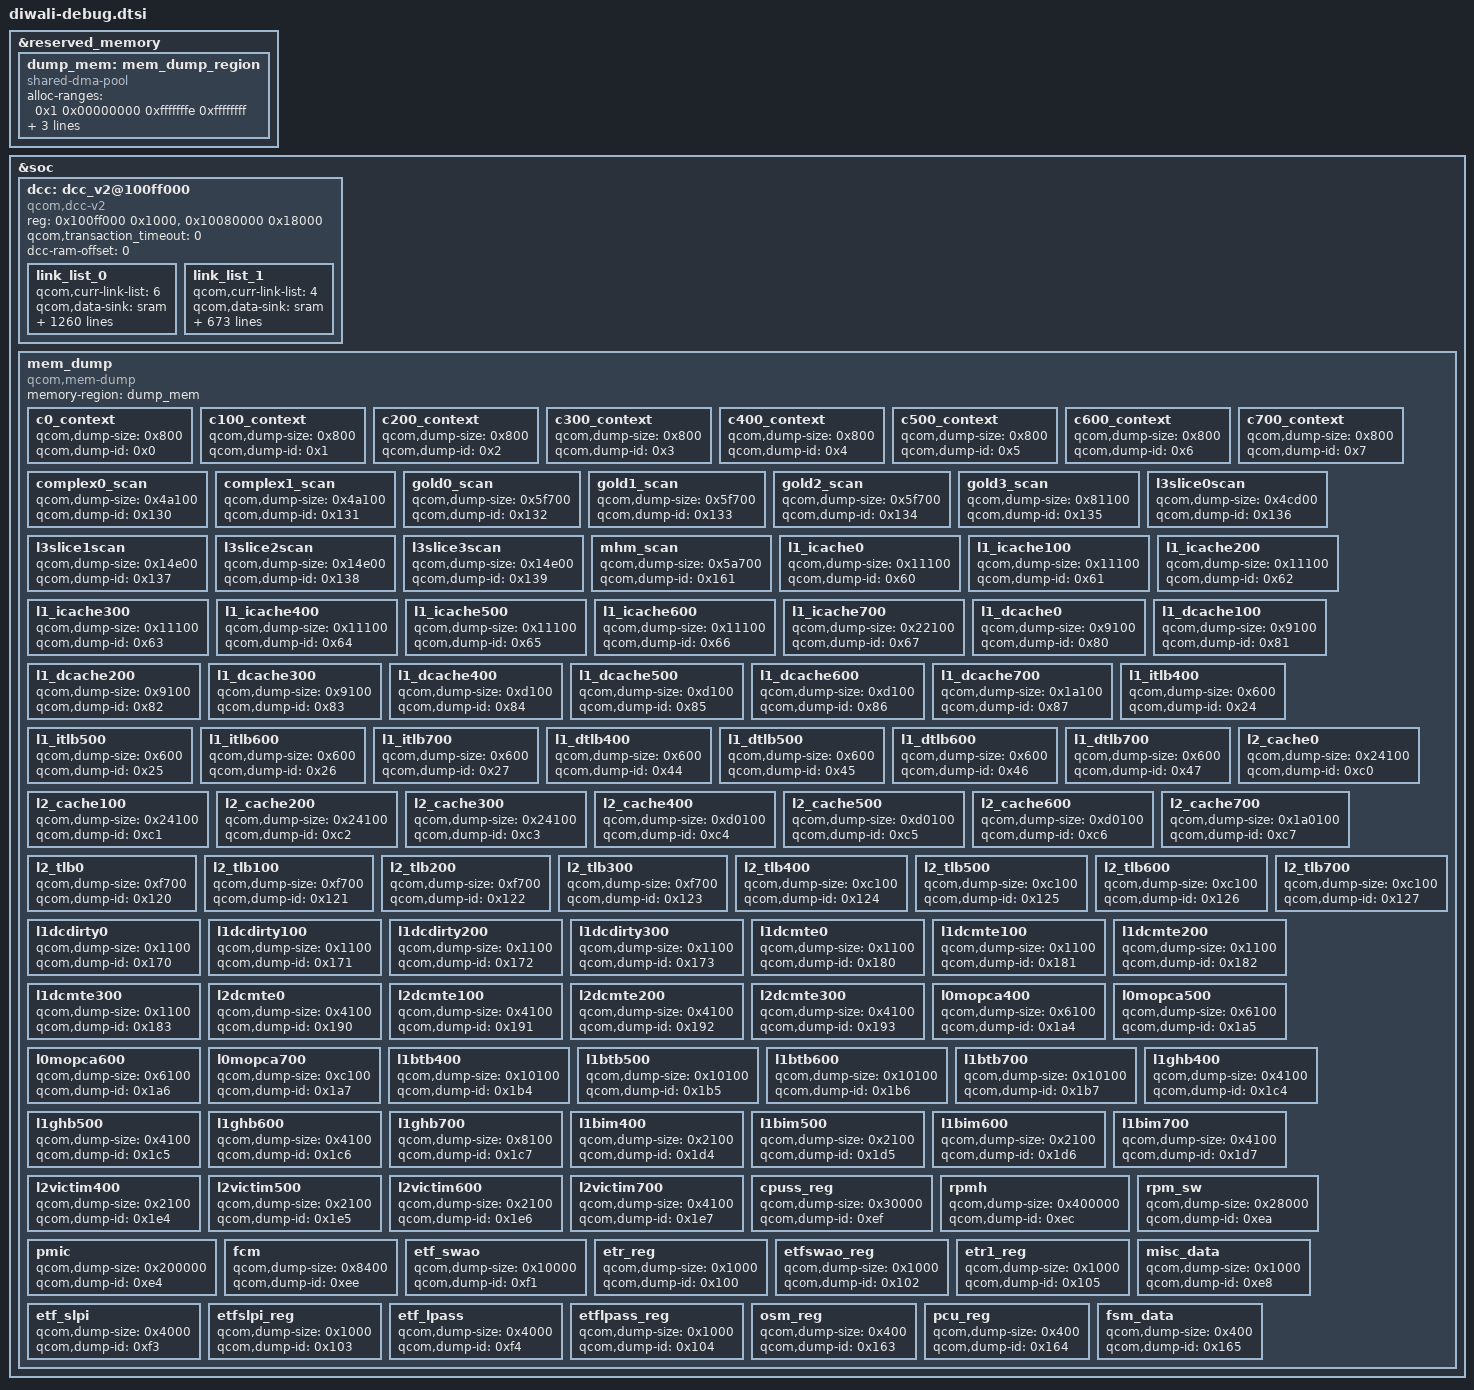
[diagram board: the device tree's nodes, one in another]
#include <dt-bindings/soc/qcom,dcc_v2.h>

&reserved_memory {
	#address-cells = <2>;
	#size-cells = <2>;
	ranges;

	dump_mem: mem_dump_region {
		compatible = "shared-dma-pool";
		alloc-ranges = <0x1 0x00000000 0xfffffffe 0xffffffff>;
		reusable;
		alignment = <0x0 0x400000>;
		size = <0 0x1400000>;
	};
};

&soc {
	dcc: dcc_v2@100ff000 {
		compatible = "qcom,dcc-v2";
		reg = <0x100ff000 0x1000>,
			<0x10080000 0x18000>;

		qcom,transaction_timeout = <0>;

		reg-names = "dcc-base", "dcc-ram-base";
		dcc-ram-offset = <0>;

		link_list_0 {
			qcom,curr-link-list = <6>;
			qcom,data-sink = "sram";
			qcom,link-list = <DCC_READ 0xc222004 1 0>,
			<DCC_READ 0xc263014 1 0>,
			<DCC_READ 0xc2630e0 1 0>,
			<DCC_READ 0xc2630ec 1 0>,
			<DCC_READ 0xc2630a0 16 0>,
			<DCC_READ 0xc2630e8 1 0>,
			<DCC_READ 0xc26313c 1 0>,
			<DCC_READ 0xc223004 1 0>,
			<DCC_READ 0xc265014 1 0>,
			<DCC_READ 0xc2650e0 1 0>,
			<DCC_READ 0xc2650ec 1 0>,
			<DCC_READ 0xc2650a0 16 0>,
			<DCC_READ 0xc2650e8 1 0>,
			<DCC_READ 0xc26513c 1 0>,
			<DCC_READ 0x1780005c 1 0>,
			<DCC_READ 0x1781005c 1 0>,
			<DCC_READ 0x1782005c 1 0>,
			<DCC_READ 0x1783005c 1 0>,
			<DCC_READ 0x1784005c 1 0>,
			<DCC_READ 0x1785005c 1 0>,
			<DCC_READ 0x1786005c 1 0>,
			<DCC_READ 0x1787005c 1 0>,
			<DCC_READ 0x1740003c 1 0>,
			<DCC_READ 0x17600238 1 0>,
			<DCC_READ 0x17600240 11 0>,
			<DCC_READ 0x17600530 1 0>,
			<DCC_READ 0x1760051c 1 0>,
			<DCC_READ 0x17600524 1 0>,
			<DCC_READ 0x1760052c 1 0>,
			<DCC_READ 0x17600518 1 0>,
			<DCC_READ 0x17600520 1 0>,
			<DCC_READ 0x17600528 1 0>,
			<DCC_READ 0x17600404 3 0>,
			<DCC_READ 0x1760041c 3 0>,
			<DCC_READ 0x17600434 1 0>,
			<DCC_READ 0x1760043c 2 0>,
			<DCC_READ 0x17400438 1 0>,
			<DCC_READ 0x17600044 1 0>,
			<DCC_READ 0x17600500 1 0>,
			<DCC_READ 0x17600504 5 0>,
			<DCC_READ 0x17900908 1 0>,
			<DCC_READ 0x17900c18 1 0>,
			<DCC_READ 0x17901908 1 0>,
			<DCC_READ 0x17901c18 1 0>,
			<DCC_READ 0x17b90810 1 0>,
			<DCC_READ 0x17b90c50 1 0>,
			<DCC_READ 0x17b90814 1 0>,
			<DCC_READ 0x17b90c54 1 0>,
			<DCC_READ 0x17b90818 1 0>,
			<DCC_READ 0x17b90c58 1 0>,
			<DCC_READ 0x17b93a84 2 0>,
			<DCC_READ 0x17ba0810 1 0>,
			<DCC_READ 0x17ba0c50 1 0>,
			<DCC_READ 0x17ba0814 1 0>,
			<DCC_READ 0x17ba0c54 1 0>,
			<DCC_READ 0x17ba0818 1 0>,
			<DCC_READ 0x17ba0c58 1 0>,
			<DCC_READ 0x17ba3a84 2 0>,
			<DCC_READ 0x17b93500 80 0>,
			<DCC_READ 0x17ba3500 80 0>,
			<DCC_READ 0x17a80000 16 0>,
			<DCC_READ 0x17a82000 16 0>,
			<DCC_READ 0x17a84000 16 0>,
			<DCC_READ 0x17a86000 16 0>,
			<DCC_READ 0x17aa0000 44 0>,
			<DCC_READ 0x17aa00fc 16 0>,
			<DCC_READ 0x17aa0200 2 0>,
			<DCC_READ 0x17aa0300 1 0>,
			<DCC_READ 0x17aa0400 1 0>,
			<DCC_READ 0x17aa0500 1 0>,
			<DCC_READ 0x17aa0600 1 0>,
			<DCC_READ 0x17aa0700 5 0>,
			<DCC_WRITE 0x17a80000 0x8007 0>,
			<DCC_READ 0x17a80000 1 0>,
			<DCC_WRITE 0x17a80024 0x0 0>,
			<DCC_READ 0x17a80024 1 0>,
			<DCC_WRITE 0x17a80020 0x0 0>,
			<DCC_READ 0x17a80020 1 0>,
			<DCC_READ 0x17a80038 1 0>,
			<DCC_WRITE 0x17a80020 0x40 0>,
			<DCC_READ 0x17a80020 1 0>,
			<DCC_READ 0x17a80038 1 0>,
			<DCC_WRITE 0x17a80020 0x80 0>,
			<DCC_READ 0x17a80020 1 0>,
			<DCC_READ 0x17a80038 1 0>,
			<DCC_WRITE 0x17a80020 0xc0 0>,
			<DCC_READ 0x17a80020 1 0>,
			<DCC_READ 0x17a80038 1 0>,
			<DCC_WRITE 0x17a80020 0x100 0>,
			<DCC_READ 0x17a80020 1 0>,
			<DCC_READ 0x17a80038 1 0>,
			<DCC_WRITE 0x17a80020 0x140 0>,
			<DCC_READ 0x17a80020 1 0>,
			<DCC_READ 0x17a80038 1 0>,
			<DCC_WRITE 0x17a80020 0x180 0>,
			<DCC_READ 0x17a80020 1 0>,
			<DCC_READ 0x17a80038 1 0>,
			<DCC_WRITE 0x17a80020 0x1c0 0>,
			<DCC_READ 0x17a80020 1 0>,
			<DCC_READ 0x17a80038 1 0>,
			<DCC_WRITE 0x17a80020 0x200 0>,
			<DCC_READ 0x17a80020 1 0>,
			<DCC_READ 0x17a80038 1 0>,
			<DCC_WRITE 0x17a80020 0x240 0>,
			<DCC_READ 0x17a80020 1 0>,
			<DCC_READ 0x17a80038 1 0>,
			<DCC_WRITE 0x17a80020 0x280 0>,
			<DCC_READ 0x17a80020 1 0>,
			<DCC_READ 0x17a80038 1 0>,
			<DCC_WRITE 0x17a80020 0x2c0 0>,
			<DCC_READ 0x17a80020 1 0>,
			<DCC_READ 0x17a80038 1 0>,
			<DCC_WRITE 0x17a80020 0x300 0>,
			<DCC_READ 0x17a80020 1 0>,
			<DCC_READ 0x17a80038 1 0>,
			<DCC_WRITE 0x17a80020 0x340 0>,
			<DCC_READ 0x17a80020 1 0>,
			<DCC_READ 0x17a80038 1 0>,
			<DCC_WRITE 0x17a80020 0x380 0>,
			<DCC_READ 0x17a80020 1 0>,
			<DCC_READ 0x17a80038 1 0>,
			<DCC_WRITE 0x17a80020 0x3c0 0>,
			<DCC_READ 0x17a80020 1 0>,
			<DCC_READ 0x17a80038 1 0>,
			<DCC_WRITE 0x17a80024 0x4000 0>,
			<DCC_READ 0x17a80024 1 0>,
			<DCC_WRITE 0x17a80020 0x0 0>,
			<DCC_READ 0x17a80020 1 0>,
			<DCC_WRITE 0x17a80020 0x0 0>,
			<DCC_READ 0x17a80020 1 0>,
			<DCC_WRITE 0x17a80020 0x0 0>,
			<DCC_READ 0x17a80020 1 0>,
			<DCC_READ 0x17a80038 1 0>,
			<DCC_WRITE 0x17a80020 0x40 0>,
			<DCC_READ 0x17a80020 1 0>,
			<DCC_READ 0x17a80038 1 0>,
			<DCC_WRITE 0x17a82000 0x8007 0>,
			<DCC_READ 0x17a82000 1 0>,
			<DCC_WRITE 0x17a82024 0x0 0>,
			<DCC_READ 0x17a82024 1 0>,
			<DCC_WRITE 0x17a82020 0x0 0>,
			<DCC_READ 0x17a82020 1 0>,
			<DCC_READ 0x17a82038 1 0>,
			<DCC_WRITE 0x17a82020 0x40 0>,
			<DCC_READ 0x17a82020 1 0>,
			<DCC_READ 0x17a82038 1 0>,
			<DCC_WRITE 0x17a82020 0x80 0>,
			<DCC_READ 0x17a82020 1 0>,
			<DCC_READ 0x17a82038 1 0>,
			<DCC_WRITE 0x17a82020 0xc0 0>,
			<DCC_READ 0x17a82020 1 0>,
			<DCC_READ 0x17a82038 1 0>,
			<DCC_WRITE 0x17a82020 0x100 0>,
			<DCC_READ 0x17a82020 1 0>,
			<DCC_READ 0x17a82038 1 0>,
			<DCC_WRITE 0x17a82020 0x140 0>,
			<DCC_READ 0x17a82020 1 0>,
			<DCC_READ 0x17a82038 1 0>,
			<DCC_WRITE 0x17a82020 0x180 0>,
			<DCC_READ 0x17a82020 1 0>,
			<DCC_READ 0x17a82038 1 0>,
			<DCC_WRITE 0x17a82020 0x1c0 0>,
			<DCC_READ 0x17a82020 1 0>,
			<DCC_READ 0x17a82038 1 0>,
			<DCC_WRITE 0x17a82020 0x200 0>,
			<DCC_READ 0x17a82020 1 0>,
			<DCC_READ 0x17a82038 1 0>,
			<DCC_WRITE 0x17a82020 0x240 0>,
			<DCC_READ 0x17a82020 1 0>,
			<DCC_READ 0x17a82038 1 0>,
			<DCC_WRITE 0x17a82020 0x280 0>,
			<DCC_READ 0x17a82020 1 0>,
			<DCC_READ 0x17a82038 1 0>,
			<DCC_WRITE 0x17a82020 0x2c0 0>,
			<DCC_READ 0x17a82020 1 0>,
			<DCC_READ 0x17a82038 1 0>,
			<DCC_WRITE 0x17a82020 0x300 0>,
			<DCC_READ 0x17a82020 1 0>,
			<DCC_READ 0x17a82038 1 0>,
			<DCC_WRITE 0x17a82020 0x340 0>,
			<DCC_READ 0x17a82020 1 0>,
			<DCC_READ 0x17a82038 1 0>,
			<DCC_WRITE 0x17a82020 0x380 0>,
			<DCC_READ 0x17a82020 1 0>,
			<DCC_READ 0x17a82038 1 0>,
			<DCC_WRITE 0x17a82020 0x3c0 0>,
			<DCC_READ 0x17a82020 1 0>,
			<DCC_READ 0x17a82038 1 0>,
			<DCC_WRITE 0x17a82024 0x4000 0>,
			<DCC_READ 0x17a82024 1 0>,
			<DCC_WRITE 0x17a82020 0x0 0>,
			<DCC_READ 0x17a82020 1 0>,
			<DCC_WRITE 0x17a82020 0x0 0>,
			<DCC_READ 0x17a82020 1 0>,
			<DCC_WRITE 0x17a82020 0x0 0>,
			<DCC_READ 0x17a82020 1 0>,
			<DCC_READ 0x17a82038 1 0>,
			<DCC_WRITE 0x17a82020 0x40 0>,
			<DCC_READ 0x17a82020 1 0>,
			<DCC_READ 0x17a82038 1 0>,
			<DCC_WRITE 0x17a84000 0x8007 0>,
			<DCC_READ 0x17a84000 1 0>,
			<DCC_WRITE 0x17a84024 0x0 0>,
			<DCC_READ 0x17a84024 1 0>,
			<DCC_WRITE 0x17a84020 0x0 0>,
			<DCC_READ 0x17a84020 1 0>,
			<DCC_READ 0x17a84038 1 0>,
			<DCC_WRITE 0x17a84020 0x40 0>,
			<DCC_READ 0x17a84020 1 0>,
			<DCC_READ 0x17a84038 1 0>,
			<DCC_WRITE 0x17a84020 0x80 0>,
			<DCC_READ 0x17a84020 1 0>,
			<DCC_READ 0x17a84038 1 0>,
			<DCC_WRITE 0x17a84020 0xc0 0>,
			<DCC_READ 0x17a84020 1 0>,
			<DCC_READ 0x17a84038 1 0>,
			<DCC_WRITE 0x17a84020 0x100 0>,
			<DCC_READ 0x17a84020 1 0>,
			<DCC_READ 0x17a84038 1 0>,
			<DCC_WRITE 0x17a84020 0x140 0>,
			<DCC_READ 0x17a84020 1 0>,
			<DCC_READ 0x17a84038 1 0>,
			<DCC_WRITE 0x17a84020 0x180 0>,
			<DCC_READ 0x17a84020 1 0>,
			<DCC_READ 0x17a84038 1 0>,
			<DCC_WRITE 0x17a84020 0x1c0 0>,
			<DCC_READ 0x17a84020 1 0>,
			<DCC_READ 0x17a84038 1 0>,
			<DCC_WRITE 0x17a84020 0x200 0>,
			<DCC_READ 0x17a84020 1 0>,
			<DCC_READ 0x17a84038 1 0>,
			<DCC_WRITE 0x17a84020 0x240 0>,
			<DCC_READ 0x17a84020 1 0>,
			<DCC_READ 0x17a84038 1 0>,
			<DCC_WRITE 0x17a84020 0x280 0>,
			<DCC_READ 0x17a84020 1 0>,
			<DCC_READ 0x17a84038 1 0>,
			<DCC_WRITE 0x17a84020 0x2c0 0>,
			<DCC_READ 0x17a84020 1 0>,
			<DCC_READ 0x17a84038 1 0>,
			<DCC_WRITE 0x17a84020 0x300 0>,
			<DCC_READ 0x17a84020 1 0>,
			<DCC_READ 0x17a84038 1 0>,
			<DCC_WRITE 0x17a84020 0x340 0>,
			<DCC_READ 0x17a84020 1 0>,
			<DCC_READ 0x17a84038 1 0>,
			<DCC_WRITE 0x17a84020 0x380 0>,
			<DCC_READ 0x17a84020 1 0>,
			<DCC_READ 0x17a84038 1 0>,
			<DCC_WRITE 0x17a84020 0x3c0 0>,
			<DCC_READ 0x17a84020 1 0>,
			<DCC_READ 0x17a84038 1 0>,
			<DCC_WRITE 0x17a84024 0x4000 0>,
			<DCC_READ 0x17a84024 1 0>,
			<DCC_WRITE 0x17a84020 0x0 0>,
			<DCC_READ 0x17a84020 1 0>,
			<DCC_WRITE 0x17a84020 0x0 0>,
			<DCC_READ 0x17a84020 1 0>,
			<DCC_WRITE 0x17a84020 0x0 0>,
			<DCC_READ 0x17a84020 1 0>,
			<DCC_READ 0x17a84038 1 0>,
			<DCC_WRITE 0x17a84020 0x40 0>,
			<DCC_READ 0x17a84020 1 0>,
			<DCC_READ 0x17a84038 1 0>,
			<DCC_WRITE 0x17a86000 0x8007 0>,
			<DCC_READ 0x17a86000 1 0>,
			<DCC_WRITE 0x17a86024 0x0 0>,
			<DCC_READ 0x17a86024 1 0>,
			<DCC_WRITE 0x17a86020 0x0 0>,
			<DCC_READ 0x17a86020 1 0>,
			<DCC_READ 0x17a86038 1 0>,
			<DCC_WRITE 0x17a86020 0x40 0>,
			<DCC_READ 0x17a86020 1 0>,
			<DCC_READ 0x17a86038 1 0>,
			<DCC_WRITE 0x17a86020 0x80 0>,
			<DCC_READ 0x17a86020 1 0>,
			<DCC_READ 0x17a86038 1 0>,
			<DCC_WRITE 0x17a86020 0xc0 0>,
			<DCC_READ 0x17a86020 1 0>,
			<DCC_READ 0x17a86038 1 0>,
			<DCC_WRITE 0x17a86020 0x100 0>,
			<DCC_READ 0x17a86020 1 0>,
			<DCC_READ 0x17a86038 1 0>,
			<DCC_WRITE 0x17a86020 0x140 0>,
			<DCC_READ 0x17a86020 1 0>,
			<DCC_READ 0x17a86038 1 0>,
			<DCC_WRITE 0x17a86020 0x180 0>,
			<DCC_READ 0x17a86020 1 0>,
			<DCC_READ 0x17a86038 1 0>,
			<DCC_WRITE 0x17a86020 0x1c0 0>,
			<DCC_READ 0x17a86020 1 0>,
			<DCC_READ 0x17a86038 1 0>,
			<DCC_WRITE 0x17a86020 0x200 0>,
			<DCC_READ 0x17a86020 1 0>,
			<DCC_READ 0x17a86038 1 0>,
			<DCC_WRITE 0x17a86020 0x240 0>,
			<DCC_READ 0x17a86020 1 0>,
			<DCC_READ 0x17a86038 1 0>,
			<DCC_WRITE 0x17a86020 0x280 0>,
			<DCC_READ 0x17a86020 1 0>,
			<DCC_READ 0x17a86038 1 0>,
			<DCC_WRITE 0x17a86020 0x2c0 0>,
			<DCC_READ 0x17a86020 1 0>,
			<DCC_READ 0x17a86038 1 0>,
			<DCC_WRITE 0x17a86020 0x300 0>,
			<DCC_READ 0x17a86020 1 0>,
			<DCC_READ 0x17a86038 1 0>,
			<DCC_WRITE 0x17a86020 0x340 0>,
			<DCC_READ 0x17a86020 1 0>,
			<DCC_READ 0x17a86038 1 0>,
			<DCC_WRITE 0x17a86020 0x380 0>,
			<DCC_READ 0x17a86020 1 0>,
			<DCC_READ 0x17a86038 1 0>,
			<DCC_WRITE 0x17a86020 0x3c0 0>,
			<DCC_READ 0x17a86020 1 0>,
			<DCC_READ 0x17a86038 1 0>,
			<DCC_WRITE 0x17a86024 0x4000 0>,
			<DCC_READ 0x17a86024 1 0>,
			<DCC_WRITE 0x17a86020 0x0 0>,
			<DCC_READ 0x17a86020 1 0>,
			<DCC_WRITE 0x17a86020 0x0 0>,
			<DCC_READ 0x17a86020 1 0>,
			<DCC_WRITE 0x17a86020 0x0 0>,
			<DCC_READ 0x17a86020 1 0>,
			<DCC_READ 0x17a86038 1 0>,
			<DCC_WRITE 0x17a86020 0x40 0>,
			<DCC_READ 0x17a86020 1 0>,
			<DCC_READ 0x17a86038 1 0>,
			<DCC_READ 0xc201244 1 0>,
			<DCC_READ 0xc202244 1 0>,
			<DCC_READ 0x17b00000 1 0>,
			<DCC_READ 0x17a94030 1 0>,
			<DCC_READ 0x17a9408c 1 0>,
			<DCC_WRITE 0x17a9409c 0x78 0>,
			<DCC_WRITE 0x17a9409c 0x0  0>,
			<DCC_WRITE 0x17a94048 0x1  0>,
			<DCC_WRITE 0x17a94090 0x0  0>,
			<DCC_WRITE 0x17a94090 0x25 0>,
			<DCC_READ 0x17a94098 1 0>,
			<DCC_WRITE 0x17a94048 0x1d 0>,
			<DCC_WRITE 0x17a94090 0x0  0>,
			<DCC_WRITE 0x17a94090 0x25 0>,
			<DCC_READ 0x17a94098 1 0>,
			<DCC_READ 0x17a90030 1 0>,
			<DCC_READ 0x17a9008c 1 0>,
			<DCC_WRITE 0x17a9009c 0x78 0>,
			<DCC_WRITE 0x17a9009c 0x0  0>,
			<DCC_WRITE 0x17a90048 0x1  0>,
			<DCC_WRITE 0x17a90090 0x0  0>,
			<DCC_WRITE 0x17a90090 0x25 0>,
			<DCC_READ 0x17a90098 1 0>,
			<DCC_WRITE 0x17a90048 0x1d 0>,
			<DCC_WRITE 0x17a90090 0x0  0>,
			<DCC_WRITE 0x17a90090 0x25 0>,
			<DCC_READ 0x17a90098 1 0>,
			<DCC_READ 0x17a92030 1 0>,
			<DCC_READ 0x17a9208c 1 0>,
			<DCC_WRITE 0x17a9209c 0x78 0>,
			<DCC_WRITE 0x17a9209c 0x0  0>,
			<DCC_WRITE 0x17a92048 0x1  0>,
			<DCC_WRITE 0x17a92090 0x0  0>,
			<DCC_WRITE 0x17a92090 0x25 0>,
			<DCC_READ 0x17a92098 1 0>,
			<DCC_WRITE 0x17a92048 0x1d 0>,
			<DCC_WRITE 0x17a92090 0x0  0>,
			<DCC_WRITE 0x17a92090 0x25 0>,
			<DCC_READ 0x17a92098 1 0>,
			<DCC_READ 0x17a96030 1 0>,
			<DCC_READ 0x17a9608c 1 0>,
			<DCC_WRITE 0x17a9609c 0x78 0>,
			<DCC_WRITE 0x17a9609c 0x0  0>,
			<DCC_WRITE 0x17a96048 0x1  0>,
			<DCC_WRITE 0x17a96090 0x0  0>,
			<DCC_WRITE 0x17a96090 0x25 0>,
			<DCC_READ 0x17a96098 1 0>,
			<DCC_WRITE 0x17a96048 0x1d 0>,
			<DCC_WRITE 0x17a96090 0x0  0>,
			<DCC_WRITE 0x17a96090 0x25 0>,
			<DCC_READ 0x17a96098 1 0>,
			<DCC_READ 0x17d98020 1 0>,
			<DCC_READ 0x13822000 1 0>,
			<DCC_READ 0x221c21c4 1 0>,
			<DCC_READ 0x1fc8000 1 0>,
			<DCC_READ 0x17400038 1 0>,
			<DCC_READ 0x17d91020 1 0>,
			<DCC_READ 0x17d92020 1 0>,
			<DCC_READ 0x17d93020 1 0>,
			<DCC_READ 0x17d90020 1 0>,
			<DCC_READ 0x17d9134c 1 0>,
			<DCC_READ 0x17d9234c 1 0>,
			<DCC_READ 0x17d9334c 1 0>,
			<DCC_READ 0x17d9034c 1 0>,
			<DCC_READ 0x17d91300 1 0>,
			<DCC_READ 0x17d92300 1 0>,
			<DCC_READ 0x17d93300 1 0>,
			<DCC_READ 0x17d90300 1 0>,
			<DCC_READ 0x191b0040 1 0>,
			<DCC_READ 0x191b0048 1 0>,
			<DCC_READ 0x19180010 1 0>,
			<DCC_READ 0x19180020 6 0>,
			<DCC_READ 0x19181010 1 0>,
			<DCC_READ 0x19181020 6 0>,
			<DCC_READ 0x19100010 1 0>,
			<DCC_READ 0x19100020 6 0>,
			<DCC_READ 0x19140010 1 0>,
			<DCC_READ 0x19140020 6 0>,
			<DCC_READ 0x19180410 1 0>,
			<DCC_LOOP 0x10  0 0>,
			<DCC_READ 0x19180438 1 0>,
			<DCC_READ 0x19180430 2 0>,
			<DCC_READ 0x19180430 2 0>,
			<DCC_READ 0x19180430 2 0>,
			<DCC_READ 0x19180430 2 0>,
			<DCC_LOOP 0x1  0 0>,
			<DCC_READ 0x19180408 2 0>,
			<DCC_READ 0x19181410 1 0>,
			<DCC_LOOP 0x10  0 0>,
			<DCC_READ 0x19181438 1 0>,
			<DCC_READ 0x19181430 2 0>,
			<DCC_READ 0x19181430 2 0>,
			<DCC_READ 0x19181430 2 0>,
			<DCC_READ 0x19181430 2 0>,
			<DCC_LOOP 0x1  0 0>,
			<DCC_READ 0x19181408 2 0>,
			<DCC_READ 0x19100410 1 0>,
			<DCC_LOOP 0x40  0 0>,
			<DCC_READ 0x19100438 1 0>,
			<DCC_READ 0x19100430 2 0>,
			<DCC_READ 0x19100430 2 0>,
			<DCC_READ 0x19100430 2 0>,
			<DCC_READ 0x19100430 2 0>,
			<DCC_LOOP 0x1  0 0>,
			<DCC_READ 0x19100408 2 0>,
			<DCC_READ 0x19140410 1 0>,
			<DCC_LOOP 0x40  0 0>,
			<DCC_READ 0x19140438 1 0>,
			<DCC_READ 0x19140430 2 0>,
			<DCC_READ 0x19140430 2 0>,
			<DCC_READ 0x19140430 2 0>,
			<DCC_READ 0x19140430 2 0>,
			<DCC_LOOP 0x1  0 0>,
			<DCC_READ 0x19140408 2 0>,
			<DCC_READ 0x19191018 1 0>,
			<DCC_READ 0x19191008 1 0>,
			<DCC_READ 0x19191010 2 0>,
			<DCC_READ 0x19191010 2 0>,
			<DCC_READ 0x19191010 2 0>,
			<DCC_READ 0x19191010 2 0>,
			<DCC_READ 0x19191010 2 0>,
			<DCC_READ 0x19191010 2 0>,
			<DCC_READ 0x19191010 2 0>,
			<DCC_READ 0x19191010 2 0>,
			<DCC_READ 0x19191010 2 0>,
			<DCC_READ 0x1914d018 1 0>,
			<DCC_READ 0x1914d008 1 0>,
			<DCC_READ 0x1914d010 2 0>,
			<DCC_READ 0x1914d010 2 0>,
			<DCC_READ 0x1914d010 2 0>,
			<DCC_READ 0x1914d010 2 0>,
			<DCC_READ 0x1914d010 2 0>,
			<DCC_READ 0x1910d018 1 0>,
			<DCC_READ 0x1910d008 1 0>,
			<DCC_READ 0x1910d010 2 0>,
			<DCC_READ 0x1910d010 2 0>,
			<DCC_READ 0x1910d010 2 0>,
			<DCC_READ 0x1910d010 2 0>,
			<DCC_READ 0x1910d010 2 0>,
			<DCC_READ 0x19190018 1 0>,
			<DCC_READ 0x19190008 1 0>,
			<DCC_READ 0x19190010 2 0>,
			<DCC_READ 0x19190010 2 0>,
			<DCC_READ 0x19190010 2 0>,
			<DCC_READ 0x1914c018 1 0>,
			<DCC_READ 0x1914c008 1 0>,
			<DCC_READ 0x1914c010 2 0>,
			<DCC_READ 0x1914c010 2 0>,
			<DCC_READ 0x1914c010 2 0>,
			<DCC_READ 0x1914c010 2 0>,
			<DCC_READ 0x1910c018 1 0>,
			<DCC_READ 0x1910c008 1 0>,
			<DCC_READ 0x1910c010 2 0>,
			<DCC_READ 0x1910c010 2 0>,
			<DCC_READ 0x1910c010 2 0>,
			<DCC_READ 0x1910c010 2 0>,
			<DCC_READ 0x19121010 1 0>,
			<DCC_READ 0x19123010 1 0>,
			<DCC_READ 0x191a1010 1 0>,
			<DCC_READ 0x191a4010 1 0>,
			<DCC_READ 0x191a5010 1 0>,
			<DCC_READ 0x191a0010 1 0>,
			<DCC_READ 0x19160010 1 0>,
			<DCC_READ 0x19120010 1 0>,
			<DCC_READ 0x191a6010 1 0>,
			<DCC_READ 0x19122010 1 0>,
			<DCC_READ 0x191a2010 1 0>,
			<DCC_READ 0x191a3010 1 0>,
			<DCC_READ 0x19161010 1 0>,
			<DCC_READ 0x19162010 1 0>,
			<DCC_READ 0x19163010 1 0>,
			<DCC_READ 0x3d0201c 1 0>,
			<DCC_READ 0x3d00000 1 0>,
			<DCC_READ 0x3d00008 1 0>,
			<DCC_READ 0x3d00044 1 0>,
			<DCC_READ 0x3d00058 6 0>,
			<DCC_READ 0x3d0007c 20 0>,
			<DCC_READ 0x3d000e0 5 0>,
			<DCC_READ 0x3d00108 1 0>,
			<DCC_READ 0x3d00110 1 0>,
			<DCC_READ 0x3d0011c 1 0>,
			<DCC_READ 0x3d00124 2 0>,
			<DCC_READ 0x3d00140 1 0>,
			<DCC_READ 0x3d00158 1 0>,
			<DCC_READ 0x3d002b4 2 0>,
			<DCC_READ 0x3d002c0 1 0>,
			<DCC_READ 0x3d002d0 1 0>,
			<DCC_READ 0x3d002e0 1 0>,
			<DCC_READ 0x3d002f0 1 0>,
			<DCC_READ 0x3d00300 1 0>,
			<DCC_READ 0x3d00310 1 0>,
			<DCC_READ 0x3d00320 1 0>,
			<DCC_READ 0x3d00330 1 0>,
			<DCC_READ 0x3d00340 1 0>,
			<DCC_READ 0x3d00350 1 0>,
			<DCC_READ 0x3d00360 1 0>,
			<DCC_READ 0x3d00370 1 0>,
			<DCC_READ 0x3d00380 1 0>,
			<DCC_READ 0x3d00390 1 0>,
			<DCC_READ 0x3d003a0 1 0>,
			<DCC_READ 0x3d003b0 1 0>,
			<DCC_READ 0x3d003c0 1 0>,
			<DCC_READ 0x3d003d0 1 0>,
			<DCC_READ 0x3d003e0 1 0>,
			<DCC_READ 0x3d00400 1 0>,
			<DCC_READ 0x3d00410 8 0>,
			<DCC_READ 0x3d0043c 15 0>,
			<DCC_READ 0x3d00800 14 0>,
			<DCC_READ 0x3d00840 4 0>,
			<DCC_READ 0x3d00854 41 0>,
			<DCC_READ 0x3d01444 1 0>,
			<DCC_READ 0x3d014d4 1 0>,
			<DCC_READ 0x3d017f0 4 0>,
			<DCC_READ 0x3d99800 8 0>,
			<DCC_READ 0x3d99828 1 0>,
			<DCC_READ 0x3d9983c 1 0>,
			<DCC_READ 0x3d998ac 1 0>,
			<DCC_READ 0x18101c 2 0>,
			<DCC_READ 0x3d94000 2 0>,
			<DCC_READ 0x3d95000 4 0>,
			<DCC_READ 0x3d96000 4 0>,
			<DCC_READ 0x3d97000 4 0>,
			<DCC_READ 0x3d98000 4 0>,
			<DCC_READ 0x3d99000 6 0>,
			<DCC_READ 0x3d99050 10 0>,
			<DCC_READ 0x3d990a8 2 0>,
			<DCC_READ 0x3d990b8 3 0>,
			<DCC_READ 0x3d990c8 1 0>,
			<DCC_READ 0x3d99104 8 0>,
			<DCC_READ 0x3d99130 2 0>,
			<DCC_READ 0x3d9913c 7 0>,
			<DCC_READ 0x3d99198 3 0>,
			<DCC_READ 0x3d991e0 3 0>,
			<DCC_READ 0x3d99224 2 0>,
			<DCC_READ 0x3d99280 4 0>,
			<DCC_READ 0x3d992cc 3 0>,
			<DCC_READ 0x3d99314 3 0>,
			<DCC_READ 0x3d99358 3 0>,
			<DCC_READ 0x3d993a0 2 0>,
			<DCC_READ 0x3d993e4 4 0>,
			<DCC_READ 0x3d9942c 2 0>,
			<DCC_READ 0x3d99470 3 0>,
			<DCC_READ 0x3d99500 4 0>,
			<DCC_READ 0x3d99528 39 0>,
			<DCC_READ 0x3d90000 15 0>,
			<DCC_READ 0x3d91000 15 0>,
			<DCC_READ 0x3de0000 21 0>,
			<DCC_READ 0x3de00d0 1 0>,
			<DCC_READ 0x3de00d8 1 0>,
			<DCC_READ 0x3de0100 3 0>,
			<DCC_READ 0x3de0200 5 0>,
			<DCC_READ 0x3de0400 3 0>,
			<DCC_READ 0x3de0450 1 0>,
			<DCC_READ 0x3de0460 2 0>,
			<DCC_READ 0x3de0490 11 0>,
			<DCC_READ 0x3de0500 1 0>,
			<DCC_READ 0x3de0600 1 0>,
			<DCC_READ 0x3de0d00 2 0>,
			<DCC_READ 0x3de0d10 4 0>,
			<DCC_READ 0x3de0d30 5 0>,
			<DCC_READ 0x3de3d44 1 0>,
			<DCC_READ 0x3de3d4c 2 0>,
			<DCC_READ 0x3d8ec0c 1 0>,
			<DCC_READ 0x3d8ec14 2 0>,
			<DCC_READ 0x3d8ec30 3 0>,
			<DCC_READ 0x3d8ec40 4 0>,
			<DCC_READ 0x3d8ec54 1 0>,
			<DCC_READ 0x3d8eca0 1 0>,
			<DCC_READ 0x3d8ecc0 1 0>,
			<DCC_READ 0x3d7d018 3 0>,
			<DCC_READ 0x3d7e440 2 0>,
			<DCC_READ 0x3d7e480 2 0>,
			<DCC_READ 0x3d7e490 2 0>,
			<DCC_READ 0x3d7e4a0 2 0>,
			<DCC_READ 0x3d7e4b0 2 0>,
			<DCC_READ 0x3d7e5c0 10 0>,
			<DCC_READ 0x3d7e648 2 0>,
			<DCC_READ 0x3d7e658 9 0>,
			<DCC_READ 0x3d7e7c0 2 0>,
			<DCC_READ 0x17800010 1 0>,
			<DCC_READ 0x17800024 1 0>,
			<DCC_READ 0x17800038 6 0>,
			<DCC_READ 0x17800058 4 0>,
			<DCC_READ 0x1780006c 1 0>,
			<DCC_READ 0x178000f0 2 0>,
			<DCC_READ 0x17810010 1 0>,
			<DCC_READ 0x17810024 1 0>,
			<DCC_READ 0x17810038 6 0>,
			<DCC_READ 0x17810058 4 0>,
			<DCC_READ 0x1781006c 1 0>,
			<DCC_READ 0x178100f0 2 0>,
			<DCC_READ 0x17820010 1 0>,
			<DCC_READ 0x17820024 1 0>,
			<DCC_READ 0x17820038 6 0>,
			<DCC_READ 0x17820058 4 0>,
			<DCC_READ 0x178200f0 2 0>,
			<DCC_READ 0x17830010 1 0>,
			<DCC_READ 0x17830024 1 0>,
			<DCC_READ 0x17830038 6 0>,
			<DCC_READ 0x17830058 4 0>,
			<DCC_READ 0x178300f0 2 0>,
			<DCC_READ 0x17840010 1 0>,
			<DCC_READ 0x17840024 1 0>,
			<DCC_READ 0x17840038 6 0>,
			<DCC_READ 0x17840058 4 0>,
			<DCC_READ 0x178400f0 2 0>,
			<DCC_READ 0x17850010 1 0>,
			<DCC_READ 0x17850024 1 0>,
			<DCC_READ 0x17850038 6 0>,
			<DCC_READ 0x17850058 4 0>,
			<DCC_READ 0x178500f0 2 0>,
			<DCC_READ 0x17860010 1 0>,
			<DCC_READ 0x17860024 1 0>,
			<DCC_READ 0x17860038 6 0>,
			<DCC_READ 0x17860058 4 0>,
			<DCC_READ 0x178600f0 2 0>,
			<DCC_READ 0x17870010 1 0>,
			<DCC_READ 0x17870024 1 0>,
			<DCC_READ 0x17870038 6 0>,
			<DCC_READ 0x17870058 4 0>,
			<DCC_READ 0x178700f0 2 0>,
			<DCC_READ 0x178a0010 1 0>,
			<DCC_READ 0x178a0024 1 0>,
			<DCC_READ 0x178a0038 6 0>,
			<DCC_READ 0x178a006c 5 0>,
			<DCC_READ 0x178a0084 1 0>,
			<DCC_READ 0x178a00f4 5 0>,
			<DCC_READ 0x178a0118 9 0>,
			<DCC_READ 0x178a0158 5 0>,
			<DCC_READ 0x178a0170 2 0>,
			<DCC_READ 0x178a0188 5 0>,
			<DCC_READ 0x178a01ac 6 0>,
			<DCC_READ 0x178a01c8 1 0>,
			<DCC_READ 0x17880010 1 0>,
			<DCC_READ 0x17880024 1 0>,
			<DCC_READ 0x17880038 6 0>,
			<DCC_READ 0x17890010 1 0>,
			<DCC_READ 0x17890024 1 0>,
			<DCC_READ 0x17890038 6 0>,
			<DCC_READ 0x178a0204 1 0>,
			<DCC_READ 0x178a0244 1 0>,
			<DCC_READ 0x17e30000 1 0>,
			<DCC_READ 0x17e30008 1 0>,
			<DCC_READ 0x17e30010 1 0>,
			<DCC_READ 0x17e80000 1 0>,
			<DCC_READ 0x17e80008 1 0>,
			<DCC_READ 0x17e80010 1 0>,
			<DCC_READ 0x17f80000 1 0>,
			<DCC_READ 0x17f80008 1 0>,
			<DCC_READ 0x17f80010 1 0>,
			<DCC_READ 0x18080000 1 0>,
			<DCC_READ 0x18080008 1 0>,
			<DCC_READ 0x18080010 1 0>,
			<DCC_READ 0x18180000 1 0>,
			<DCC_READ 0x18180008 1 0>,
			<DCC_READ 0x18180010 1 0>,
			<DCC_READ 0x18280000 1 0>,
			<DCC_READ 0x18280008 1 0>,
			<DCC_READ 0x18280010 1 0>,
			<DCC_READ 0x18380000 1 0>,
			<DCC_READ 0x18380008 1 0>,
			<DCC_READ 0x18380010 1 0>,
			<DCC_READ 0x18480000 1 0>,
			<DCC_READ 0x18480008 1 0>,
			<DCC_READ 0x18480010 1 0>,
			<DCC_READ 0x18580000 1 0>,
			<DCC_READ 0x18580008 1 0>,
			<DCC_READ 0x18580010 1 0>,
			<DCC_READ 0x19080024 1 0>,
			<DCC_READ 0x1908002c 1 0>,
			<DCC_READ 0x19080034 1 0>,
			<DCC_READ 0x1908003c 1 0>,
			<DCC_READ 0x19080044 1 0>,
			<DCC_READ 0x1908004c 1 0>,
			<DCC_READ 0x19080058 2 0>,
			<DCC_READ 0x190800c8 1 0>,
			<DCC_READ 0x190800d4 1 0>,
			<DCC_READ 0x190800e0 1 0>,
			<DCC_READ 0x19080144 1 0>,
			<DCC_READ 0x1908014c 1 0>,
			<DCC_READ 0x19080174 1 0>,
			<DCC_READ 0x1908017c 1 0>,
			<DCC_READ 0x19080184 1 0>,
			<DCC_READ 0x1908018c 1 0>,
			<DCC_READ 0x19080194 1 0>,
			<DCC_READ 0x1908019c 1 0>,
			<DCC_READ 0x190801a4 1 0>,
			<DCC_READ 0x190801ac 3 0>,
			<DCC_READ 0x190a9168 2>,
			<DCC_READ 0x190a9178 2 0>,
			<DCC_READ 0x190a9188 2 0>,
			<DCC_READ 0x190a9198 2 0>,
			<DCC_READ 0x190a91c8 1 0>,
			<DCC_READ 0x190aa044 1 0>,
			<DCC_READ 0x190a80e4 2 0>,
			<DCC_READ 0x190a80f8 1 0>,
			<DCC_READ 0x190a80f8 5 0>,
			<DCC_READ 0x190a8150 2 0>,
			<DCC_READ 0x190a8164 2 0>,
			<DCC_READ 0x190a8174 4 0>,
			<DCC_READ 0x190a819c 1 0>,
			<DCC_READ 0x190a81cc 1 0>,
			<DCC_READ 0x190a8498 1 0>,
			<DCC_READ 0x190a8804 1 0>,
			<DCC_READ 0x190a8804 1 0>,
			<DCC_READ 0x190a880c 1 0>,
			<DCC_READ 0x190a880c 1 0>,
			<DCC_READ 0x190a8834 1 0>,
			<DCC_READ 0x190a8840 2 0>,
			<DCC_READ 0x190a8850 2 0>,
			<DCC_READ 0x190a8860 1 0>,
			<DCC_READ 0x190a8860 2 0>,
			<DCC_READ 0x190a8864 2 0>,
			<DCC_READ 0x190a8868 1 0>,
			<DCC_READ 0x190a8878 1 0>,
			<DCC_READ 0x190a888c 1 0>,
			<DCC_READ 0x190a8900 1 0>,
			<DCC_READ 0x190a9134 2 0>,
			<DCC_READ 0x190a9198 2 0>,
			<DCC_READ 0x190a91c4 2 0>,
			<DCC_READ 0x190aa034 3 0>,
			<DCC_READ 0x190aa044 1 0>,
			<DCC_READ 0x190aa04c 1 0>,
			<DCC_READ 0x190a8884 1 0>,
			<DCC_READ 0x190a9140 1 0>,
			<DCC_READ 0x190a0008 2 0>,
			<DCC_READ 0x190a1008 2 0>,
			<DCC_READ 0x19220344 9 0>,
			<DCC_READ 0x19220370 7 0>,
			<DCC_READ 0x19220480 1 0>,
			<DCC_READ 0x19222400 26 0>,
			<DCC_READ 0x19222470 5 0>,
			<DCC_READ 0x1922320c 1 0>,
			<DCC_READ 0x19223214 2 0>,
			<DCC_READ 0x19223220 4 0>,
			<DCC_READ 0x19223308 1 0>,
			<DCC_READ 0x19223318 1 0>,
			<DCC_READ 0x19223318 1 0>,
			<DCC_READ 0x1922358c 1 0>,
			<DCC_READ 0x19234010 1 0>,
			<DCC_READ 0x1923801c 8 0>,
			<DCC_READ 0x19238050 1 0>,
			<DCC_READ 0x19238100 1 0>,
			<DCC_READ 0x19238100 7 0>,
			<DCC_READ 0x1923c004 1 0>,
			<DCC_READ 0x1923c014 1 0>,
			<DCC_READ 0x1923c020 1 0>,
			<DCC_READ 0x1923c030 1 0>,
			<DCC_READ 0x1923c05c 3 0>,
			<DCC_READ 0x1923c074 1 0>,
			<DCC_READ 0x1923c088 1 0>,
			<DCC_READ 0x1923c0a0 1 0>,
			<DCC_READ 0x1923c0b0 1 0>,
			<DCC_READ 0x1923c0c0 1 0>,
			<DCC_READ 0x1923c0d0 1 0>,
			<DCC_READ 0x1923c0e0 1 0>,
			<DCC_READ 0x1923c0f0 1 0>,
			<DCC_READ 0x1923c100 1 0>,
			<DCC_READ 0x1923d064 1 0>,
			<DCC_READ 0x19240008 6 0>,
			<DCC_READ 0x19240028 1 0>,
			<DCC_READ 0x1924203c 3 0>,
			<DCC_READ 0x19242044 2 0>,
			<DCC_READ 0x19242048 2 0>,
			<DCC_READ 0x1924204c 10 0>,
			<DCC_READ 0x1924208c 1 0>,
			<DCC_READ 0x192420b0 1 0>,
			<DCC_READ 0x192420b0 1 0>,
			<DCC_READ 0x192420b8 3 0>,
			<DCC_READ 0x192420f4 1 0>,
			<DCC_READ 0x192420fc 3 0>,
			<DCC_READ 0x19242104 5 0>,
			<DCC_READ 0x19242114 1 0>,
			<DCC_READ 0x19242324 14 0>,
			<DCC_READ 0x19242410 1 0>,
			<DCC_READ 0x192430a8 1 0>,
			<DCC_READ 0x19248004 7 0>,
			<DCC_READ 0x19248024 1 0>,
			<DCC_READ 0x19248040 1 0>,
			<DCC_READ 0x19248048 1 0>,
			<DCC_READ 0x19249064 1 0>,
			<DCC_READ 0x1924c000 1 0>,
			<DCC_READ 0x1924c030 1 0>,
			<DCC_READ 0x1924c030 3 0>,
			<DCC_READ 0x1924c040 3 0>,
			<DCC_READ 0x1924c054 2 0>,
			<DCC_READ 0x1924c078 1 0>,
			<DCC_READ 0x1924c108 1 0>,
			<DCC_READ 0x1924c110 1 0>,
			<DCC_READ 0x19250020 1 0>,
			<DCC_READ 0x19250020 1 0>,
			<DCC_READ 0x19251054 1 0>,
			<DCC_READ 0x19252014 3 0>,
			<DCC_READ 0x19252028 1 0>,
			<DCC_READ 0x19252028 17 0>,
			<DCC_READ 0x19252070 8 0>,
			<DCC_READ 0x19252098 1 0>,
			<DCC_READ 0x192520a0 1 0>,
			<DCC_READ 0x192520b4 1 0>,
			<DCC_READ 0x192520c0 1 0>,
			<DCC_READ 0x192520d0 3 0>,
			<DCC_READ 0x192520f4 10 0>,
			<DCC_READ 0x19252120 12 0>,
			<DCC_READ 0x1925802c 1 0>,
			<DCC_READ 0x1925809c 2 0>,
			<DCC_READ 0x192580a8 3 0>,
			<DCC_READ 0x192580b8 1 0>,
			<DCC_READ 0x192580c0 7 0>,
			<DCC_READ 0x192580e0 1 0>,
			<DCC_READ 0x192580e8 1 0>,
			<DCC_READ 0x192580f0 1 0>,
			<DCC_READ 0x192580f8 1 0>,
			<DCC_READ 0x19258100 1 0>,
			<DCC_READ 0x19258108 1 0>,
			<DCC_READ 0x19258110 1 0>,
			<DCC_READ 0x19258118 1 0>,
			<DCC_READ 0x19258120 1 0>,
			<DCC_READ 0x19258128 1 0>,
			<DCC_READ 0x19258210 3 0>,
			<DCC_READ 0x19259010 1 0>,
			<DCC_READ 0x19259070 1 0>,
			<DCC_READ 0x1925b004 1 0>,
			<DCC_READ 0x1926004c 1 0>,
			<DCC_READ 0x1926004c 2 0>,
			<DCC_READ 0x19260050 2 0>,
			<DCC_READ 0x19260054 2 0>,
			<DCC_READ 0x19260058 2 0>,
			<DCC_READ 0x1926005c 2 0>,
			<DCC_READ 0x19260060 2 0>,
			<DCC_READ 0x19260064 2 0>,
			<DCC_READ 0x19260068 3 0>,
			<DCC_READ 0x19260078 1 0>,
			<DCC_READ 0x1926020c 1 0>,
			<DCC_READ 0x19260214 1 0>,
			<DCC_READ 0x19261084 1 0>,
			<DCC_READ 0x19262020 1 0>,
			<DCC_READ 0x19263020 1 0>,
			<DCC_READ 0x19264020 1 0>,
			<DCC_READ 0x19265020 1 0>,
			<DCC_READ 0x19320344 2 0>,
			<DCC_READ 0x19320348 8 0>,
			<DCC_READ 0x19320370 7 0>,
			<DCC_READ 0x19320480 1 0>,
			<DCC_READ 0x19320480 1 0>,
			<DCC_READ 0x19322400 1 0>,
			<DCC_READ 0x19322400 26 0>,
			<DCC_READ 0x19322470 5 0>,
			<DCC_READ 0x1932320c 1 0>,
			<DCC_READ 0x19323214 2 0>,
			<DCC_READ 0x19323220 1 0>,
			<DCC_READ 0x19323220 2 0>,
			<DCC_READ 0x19323224 2 0>,
			<DCC_READ 0x19323228 2 0>,
			<DCC_READ 0x1932322c 1 0>,
			<DCC_READ 0x19323308 1 0>,
			<DCC_READ 0x19323308 1 0>,
			<DCC_READ 0x19323318 1 0>,
			<DCC_READ 0x19323318 1 0>,
			<DCC_READ 0x1932358c 1 0>,
			<DCC_READ 0x19334010 1 0>,
			<DCC_READ 0x1933801c 8 0>,
			<DCC_READ 0x19338050 1 0>,
			<DCC_READ 0x19338100 1 0>,
			<DCC_READ 0x19338100 7 0>,
			<DCC_READ 0x1933c004 1 0>,
			<DCC_READ 0x1933c014 1 0>,
			<DCC_READ 0x1933c020 1 0>,
			<DCC_READ 0x1933c030 1 0>,
			<DCC_READ 0x1933c05c 3 0>,
			<DCC_READ 0x1933c074 1 0>,
			<DCC_READ 0x1933c088 1 0>,
			<DCC_READ 0x1933c0a0 1 0>,
			<DCC_READ 0x1933c0b0 1 0>,
			<DCC_READ 0x1933c0c0 1 0>,
			<DCC_READ 0x1933c0d0 1 0>,
			<DCC_READ 0x1933c0e0 1 0>,
			<DCC_READ 0x1933c0f0 1 0>,
			<DCC_READ 0x1933c100 1 0>,
			<DCC_READ 0x1933d064 1 0>,
			<DCC_READ 0x19340008 6 0>,
			<DCC_READ 0x19340028 1 0>,
			<DCC_READ 0x1934203c 3 0>,
			<DCC_READ 0x19342044 2 0>,
			<DCC_READ 0x19342048 2 0>,
			<DCC_READ 0x1934204c 10 0>,
			<DCC_READ 0x1934208c 1 0>,
			<DCC_READ 0x193420b0 1 0>,
			<DCC_READ 0x193420b0 1 0>,
			<DCC_READ 0x193420b8 3 0>,
			<DCC_READ 0x193420f4 1 0>,
			<DCC_READ 0x193420fc 3 0>,
			<DCC_READ 0x19342104 5 0>,
			<DCC_READ 0x19342114 1 0>,
			<DCC_READ 0x19342324 14 0>,
			<DCC_READ 0x19342410 1 0>,
			<DCC_READ 0x193430a8 1 0>,
			<DCC_READ 0x19348004 1 0>,
			<DCC_READ 0x19348004 2 0>,
			<DCC_READ 0x19348008 2 0>,
			<DCC_READ 0x1934800c 2 0>,
			<DCC_READ 0x19348010 4 0>,
			<DCC_READ 0x19348024 1 0>,
			<DCC_READ 0x19348040 1 0>,
			<DCC_READ 0x19348048 1 0>,
			<DCC_READ 0x19349064 1 0>,
			<DCC_READ 0x1934c000 1 0>,
			<DCC_READ 0x1934c030 1 0>,
			<DCC_READ 0x1934c030 3 0>,
			<DCC_READ 0x1934c040 3 0>,
			<DCC_READ 0x1934c054 2 0>,
			<DCC_READ 0x1934c078 1 0>,
			<DCC_READ 0x1934c108 1 0>,
			<DCC_READ 0x1934c110 1 0>,
			<DCC_READ 0x19350020 1 0>,
			<DCC_READ 0x19350020 1 0>,
			<DCC_READ 0x19351054 1 0>,
			<DCC_READ 0x19352014 3 0>,
			<DCC_READ 0x19352028 1 0>,
			<DCC_READ 0x19352028 17 0>,
			<DCC_READ 0x19352070 8 0>,
			<DCC_READ 0x19352098 1 0>,
			<DCC_READ 0x193520a0 1 0>,
			<DCC_READ 0x193520b4 1 0>,
			<DCC_READ 0x193520c0 1 0>,
			<DCC_READ 0x193520d0 3 0>,
			<DCC_READ 0x193520f4 10 0>,
			<DCC_READ 0x19352120 12 0>,
			<DCC_READ 0x1935802c 1 0>,
			<DCC_READ 0x1935802c 1 0>,
			<DCC_READ 0x1935809c 1 0>,
			<DCC_READ 0x1935809c 2 0>,
			<DCC_READ 0x193580a8 3 0>,
			<DCC_READ 0x193580b8 1 0>,
			<DCC_READ 0x193580c0 7 0>,
			<DCC_READ 0x193580e0 1 0>,
			<DCC_READ 0x193580e8 1 0>,
			<DCC_READ 0x193580f0 1 0>,
			<DCC_READ 0x193580f8 1 0>,
			<DCC_READ 0x193580a0 1 0>,
			<DCC_READ 0x193580a8 3 0>,
			<DCC_READ 0x193580b8 1 0>,
			<DCC_READ 0x193580c0 7 0>,
			<DCC_READ 0x193580e0 1 0>,
			<DCC_READ 0x193580e8 1 0>,
			<DCC_READ 0x193580f0 1 0>,
			<DCC_READ 0x193580f8 1 0>,
			<DCC_READ 0x19358100 1 0>,
			<DCC_READ 0x19358100 1 0>,
			<DCC_READ 0x19358108 1 0>,
			<DCC_READ 0x19358108 1 0>,
			<DCC_READ 0x19358110 1 0>,
			<DCC_READ 0x19358110 1 0>,
			<DCC_READ 0x19358118 1 0>,
			<DCC_READ 0x19358118 1 0>,
			<DCC_READ 0x19358120 1 0>,
			<DCC_READ 0x19358120 1 0>,
			<DCC_READ 0x19358128 1 0>,
			<DCC_READ 0x19358128 1 0>,
			<DCC_READ 0x19358210 1 0>,
			<DCC_READ 0x19358210 2 0>,
			<DCC_READ 0x19358214 2 0>,
			<DCC_READ 0x19358218 1 0>,
			<DCC_READ 0x19359010 1 0>,
			<DCC_READ 0x19359010 1 0>,
			<DCC_READ 0x19359070 1 0>,
			<DCC_READ 0x19359070 1 0>,
			<DCC_READ 0x1935b004 1 0>,
			<DCC_READ 0x1935b004 1 0>,
			<DCC_READ 0x1936004c 1 0>,
			<DCC_READ 0x1936004c 1 0>,
			<DCC_READ 0x1936004c 2 0>,
			<DCC_READ 0x19360050 1 0>,
			<DCC_READ 0x19360050 2 0>,
			<DCC_READ 0x19360054 1 0>,
			<DCC_READ 0x19360054 2 0>,
			<DCC_READ 0x19360058 1 0>,
			<DCC_READ 0x19360058 2 0>,
			<DCC_READ 0x1936005c 1 0>,
			<DCC_READ 0x1936005c 2 0>,
			<DCC_READ 0x19360060 1 0>,
			<DCC_READ 0x19360060 2 0>,
			<DCC_READ 0x19360064 1 0>,
			<DCC_READ 0x19360064 2 0>,
			<DCC_READ 0x19360068 1 0>,
			<DCC_READ 0x19360068 3 0>,
			<DCC_READ 0x19360078 1 0>,
			<DCC_READ 0x1936020c 1 0>,
			<DCC_READ 0x19360214 1 0>,
			<DCC_READ 0x19361084 1 0>,
			<DCC_READ 0x19362020 1 0>,
			<DCC_READ 0x19363020 1 0>,
			<DCC_READ 0x19364020 1 0>,
			<DCC_READ 0x19365020 1 0>,
			<DCC_READ 0x192c5cac 3 0>,
			<DCC_READ 0x192c0080 1 0>,
			<DCC_READ 0x192c0310 1 0>,
			<DCC_READ 0x192c0400 2 0>,
			<DCC_READ 0x192c0410 6 0>,
			<DCC_READ 0x192c0430 1 0>,
			<DCC_READ 0x192c0440 1 0>,
			<DCC_READ 0x192c0448 1 0>,
			<DCC_READ 0x192c04a0 1 0>,
			<DCC_READ 0x192c04b0 4 0>,
			<DCC_READ 0x192c04d0 2 0>,
			<DCC_READ 0x192c1400 1 0>,
			<DCC_READ 0x192c1408 1 0>,
			<DCC_READ 0x192c2400 2 0>,
			<DCC_READ 0x192c2438 2 0>,
			<DCC_READ 0x192c2454 1 0>,
			<DCC_READ 0x192c3400 4 0>,
			<DCC_READ 0x192c3418 3 0>,
			<DCC_READ 0x192c4700 1 0>,
			<DCC_READ 0x192c53b0 1 0>,
			<DCC_READ 0x192c5804 1 0>,
			<DCC_READ 0x192c590c 1 0>,
			<DCC_READ 0x192c5a14 1 0>,
			<DCC_READ 0x192c5c0c 1 0>,
			<DCC_READ 0x192c5c18 2 0>,
			<DCC_READ 0x192c5c2c 2 0>,
			<DCC_READ 0x192c5c38 1 0>,
			<DCC_READ 0x192c5c4c 1 0>,
			<DCC_READ 0x192c5ca4 1 0>,
			<DCC_READ 0x192c5cac 3 0>,
			<DCC_READ 0x192c6400 1 0>,
			<DCC_READ 0x192c6418 2 0>,
			<DCC_READ 0x192c9100 1 0>,
			<DCC_READ 0x192c9110 1 0>,
			<DCC_READ 0x192c9120 1 0>,
			<DCC_READ 0x192c9180 1 0>,
			<DCC_READ 0x192c9180 2 0>,
			<DCC_READ 0x192c9184 1 0>,
			<DCC_READ 0x192c91a0 1 0>,
			<DCC_READ 0x192c91b0 1 0>,
			<DCC_READ 0x192c91c0 2 0>,
			<DCC_READ 0x192c91e0 1 0>,
			<DCC_READ 0x193c5cac 3 0>,
			<DCC_READ 0x193c0080 1 0>,
			<DCC_READ 0x193c0310 1 0>,
			<DCC_READ 0x193c0400 2 0>,
			<DCC_READ 0x193c0410 6 0>,
			<DCC_READ 0x193c0430 1 0>,
			<DCC_READ 0x193c0440 1 0>,
			<DCC_READ 0x193c0448 1 0>,
			<DCC_READ 0x193c04a0 1 0>,
			<DCC_READ 0x193c04b0 4 0>,
			<DCC_READ 0x193c04d0 2 0>,
			<DCC_READ 0x193c1400 1 0>,
			<DCC_READ 0x193c1408 1 0>,
			<DCC_READ 0x193c2400 2 0>,
			<DCC_READ 0x193c2438 2 0>,
			<DCC_READ 0x193c2454 1 0>,
			<DCC_READ 0x193c3400 4 0>,
			<DCC_READ 0x193c3418 3 0>,
			<DCC_READ 0x193c4700 1 0>,
			<DCC_READ 0x193c53b0 1 0>,
			<DCC_READ 0x193c5804 1 0>,
			<DCC_READ 0x193c590c 1 0>,
			<DCC_READ 0x193c5a14 1 0>,
			<DCC_READ 0x193c5c0c 1 0>,
			<DCC_READ 0x193c5c18 2 0>,
			<DCC_READ 0x193c5c2c 2 0>,
			<DCC_READ 0x193c5c38 1 0>,
			<DCC_READ 0x193c5c4c 1 0>,
			<DCC_READ 0x193c5ca4 1 0>,
			<DCC_READ 0x193c5cac 3 0>,
			<DCC_READ 0x193c6400 1 0>,
			<DCC_READ 0x193c6418 2 0>,
			<DCC_READ 0x193c9100 1 0>,
			<DCC_READ 0x193c9110 1 0>,
			<DCC_READ 0x193c9120 1 0>,
			<DCC_READ 0x193c9180 1 0>,
			<DCC_READ 0x193c9180 2 0>,
			<DCC_READ 0x193c9184 1 0>,
			<DCC_READ 0x193c91a0 1 0>,
			<DCC_READ 0x193c91b0 1 0>,
			<DCC_READ 0x193c91c0 2 0>,
			<DCC_READ 0x193c91e0 1 0>,
			<DCC_READ 0x192c1420 1 0>,
			<DCC_READ 0x192c1430 1 0>,
			<DCC_READ 0x193c1420 1 0>,
			<DCC_READ 0x193c1430 1 0>,
			<DCC_READ 0x190ba280 1 0>,
			<DCC_READ 0x190ba288 8 0>,
			<DCC_READ 0x192e0610 4 0>,
			<DCC_READ 0x192e0680 4 0>,
			<DCC_READ 0x193e0610 3 0>,
			<DCC_READ 0x193e0618 2 0>,
			<DCC_READ 0x193e0680 2 0>,
			<DCC_READ 0x193e0684 3 0>,
			<DCC_READ 0x193e068c 1 0>,
			<DCC_READ 0x19281e64>,
			<DCC_READ 0x19281ea0 1 0>,
			<DCC_READ 0x19281f30 2 0>,
			<DCC_READ 0x19283e64 1 0>,
			<DCC_READ 0x19283ea0 1 0>,
			<DCC_READ 0x19283f30 2 0>,
			<DCC_READ 0x1928527c 1 0>,
			<DCC_READ 0x19285290 1 0>,
			<DCC_READ 0x192854ec 1 0>,
			<DCC_READ 0x192854f4 1 0>,
			<DCC_READ 0x19285514 1 0>,
			<DCC_READ 0x1928551c 1 0>,
			<DCC_READ 0x19285524 1 0>,
			<DCC_READ 0x19285548 1 0>,
			<DCC_READ 0x19285550 1 0>,
			<DCC_READ 0x19285558 1 0>,
			<DCC_READ 0x192855b8 1 0>,
			<DCC_READ 0x192855c0 1 0>,
			<DCC_READ 0x192855ec 1 0>,
			<DCC_READ 0x19285860 1 0>,
			<DCC_READ 0x19285870 1 0>,
			<DCC_READ 0x192858a0 1 0>,
			<DCC_READ 0x192858a8 1 0>,
			<DCC_READ 0x192858b0 1 0>,
			<DCC_READ 0x192858b8 1 0>,
			<DCC_READ 0x192858d8 2 0>,
			<DCC_READ 0x192858f4 1 0>,
			<DCC_READ 0x192858fc 1 0>,
			<DCC_READ 0x19285920 1 0>,
			<DCC_READ 0x19285928 1 0>,
			<DCC_READ 0x19285944 1 0>,
			<DCC_READ 0x19286604 1 0>,
			<DCC_READ 0x1928660c 1 0>,
			<DCC_READ 0x19381e64 1 0>,
			<DCC_READ 0x19381ea0 1 0>,
			<DCC_READ 0x19381f30 2 0>,
			<DCC_READ 0x19383e64 1 0>,
			<DCC_READ 0x19383ea0 1 0>,
			<DCC_READ 0x19383f30 2 0>,
			<DCC_READ 0x1938527c 1 0>,
			<DCC_READ 0x19385290 1 0>,
			<DCC_READ 0x193854ec 1 0>,
			<DCC_READ 0x193854f4 1 0>,
			<DCC_READ 0x19385514 1 0>,
			<DCC_READ 0x1938551c 1 0>,
			<DCC_READ 0x19385524 1 0>,
			<DCC_READ 0x19385548 1 0>,
			<DCC_READ 0x19385550 1 0>,
			<DCC_READ 0x19385558 1 0>,
			<DCC_READ 0x193855b8 1 0>,
			<DCC_READ 0x193855c0 1 0>,
			<DCC_READ 0x193855ec 1 0>,
			<DCC_READ 0x19385860 1 0>,
			<DCC_READ 0x19385870 1 0>,
			<DCC_READ 0x193858a0 1 0>,
			<DCC_READ 0x193858a8 1 0>,
			<DCC_READ 0x193858b0 1 0>,
			<DCC_READ 0x193858b8 1 0>,
			<DCC_READ 0x193858d8 2 0>,
			<DCC_READ 0x193858f4 1 0>,
			<DCC_READ 0x193858fc 1 0>,
			<DCC_READ 0x19385920 1 0>,
			<DCC_READ 0x19385928 1 0>,
			<DCC_READ 0x19385944 1 0>,
			<DCC_READ 0x19386604 1 0>,
			<DCC_READ 0x1938660c 1 0>,
			<DCC_READ 0x610110 5 0>,
			<DCC_READ 0x19032020 2 0>,
			<DCC_READ 0x1908e01c 1 0>,
			<DCC_READ 0x1908e030 1 0>,
			<DCC_READ 0x19030010 1 0>,
			<DCC_READ 0x1908e008 1 0>,
			<DCC_READ 0x19032020 1 0>,
			<DCC_READ 0x1908e948 1 0>,
			<DCC_READ 0x19032024 1 0>,
			<DCC_WRITE 0x19030040 0x1 1>,
			<DCC_WRITE 0x1903005c 0x22c000 1>,
			<DCC_READ 0x19030010 1 0>,
			<DCC_WRITE 0x1903005c 0x22c001 1>,
			<DCC_READ 0x19030010 1 0>,
			<DCC_WRITE 0x1903005c 0x22c002 1>,
			<DCC_READ 0x19030010 1 0>,
			<DCC_WRITE 0x1903005c 0x22c003 1>,
			<DCC_READ 0x19030010 1 0>,
			<DCC_WRITE 0x1903005c 0x22c004 1>,
			<DCC_READ 0x19030010 1 0>,
			<DCC_WRITE 0x1903005c 0x22c005 1>,
			<DCC_READ 0x19030010 1 0>,
			<DCC_WRITE 0x1903005c 0x22c006 1>,
			<DCC_READ 0x19030010 1 0>,
			<DCC_WRITE 0x1903005c 0x22c007 1>,
			<DCC_READ 0x19030010 1 0>,
			<DCC_WRITE 0x1903005c 0x22c008 1>,
			<DCC_READ 0x19030010 1 0>,
			<DCC_WRITE 0x1903005c 0x22c009 1>,
			<DCC_READ 0x19030010 1 0>,
			<DCC_WRITE 0x1903005c 0x22c00a 1>,
			<DCC_READ 0x19030010 1 0>,
			<DCC_WRITE 0x1903005c 0x22c00b 1>,
			<DCC_READ 0x19030010 1 0>,
			<DCC_WRITE 0x1903005c 0x22c00c 1>,
			<DCC_READ 0x19030010 1 0>,
			<DCC_WRITE 0x1903005c 0x22c00d 1>,
			<DCC_READ 0x19030010 1 0>,
			<DCC_WRITE 0x1903005c 0x22c00e 1>,
			<DCC_READ 0x19030010 1 0>,
			<DCC_WRITE 0x1903005c 0x22c00f 1>,
			<DCC_READ 0x19030010 1 0>,
			<DCC_WRITE 0x1903005c 0x22c010 1>,
			<DCC_READ 0x19030010 1 0>,
			<DCC_WRITE 0x1903005c 0x22c011 1>,
			<DCC_READ 0x19030010 1 0>,
			<DCC_WRITE 0x1903005c 0x22c012 1>,
			<DCC_READ 0x19030010 1 0>,
			<DCC_WRITE 0x1903005c 0x22c013 1>,
			<DCC_READ 0x19030010 1 0>,
			<DCC_WRITE 0x1903005c 0x22c014 1>,
			<DCC_READ 0x19030010 1 0>,
			<DCC_WRITE 0x1903005c 0x22c015 1>,
			<DCC_READ 0x19030010 1 0>,
			<DCC_WRITE 0x1903005c 0x22c016 1>,
			<DCC_READ 0x19030010 1 0>,
			<DCC_WRITE 0x1903005c 0x22c017 1>,
			<DCC_READ 0x19030010 1 0>,
			<DCC_WRITE 0x1903005c 0x22c018 1>,
			<DCC_READ 0x19030010 1 0>,
			<DCC_WRITE 0x1903005c 0x22c019 1>,
			<DCC_READ 0x19030010 1 0>,
			<DCC_WRITE 0x1903005c 0x22c01a 1>,
			<DCC_READ 0x19030010 1 0>,
			<DCC_WRITE 0x1903005c 0x22c01b 1>,
			<DCC_READ 0x19030010 1 0>,
			<DCC_WRITE 0x1903005c 0x22c01c 1>,
			<DCC_READ 0x19030010 1 0>,
			<DCC_WRITE 0x1903005c 0x22c01d 1>,
			<DCC_READ 0x19030010 1 0>,
			<DCC_WRITE 0x1903005c 0x22c01e 1>,
			<DCC_READ 0x19030010 1 0>,
			<DCC_WRITE 0x1903005c 0x22c01f 1>,
			<DCC_READ 0x19030010 1 0>,
			<DCC_WRITE 0x1903005c 0x22c300 1>,
			<DCC_READ 0x19030010 1 0>,
			<DCC_WRITE 0x1903005c 0x22c341 1>,
			<DCC_READ 0x19030010 1 0>,
			<DCC_WRITE 0x1903005c 0x22c7b1 1>,
			<DCC_READ 0x19030010 1 0>,
			<DCC_READ 0x32302028 1 0>,
			<DCC_READ 0x320a4404 2 0>,
			<DCC_READ 0x323b0404 2 0>,
			<DCC_READ 0xb2b1020 2 0>;
			};

		link_list_1 {
			qcom,curr-link-list = <4>;
			qcom,data-sink = "sram";
			qcom,link-list = <DCC_READ 0x190e0010 1 0>,
			<DCC_READ 0x190e0020 8 0>,
			<DCC_READ 0x190e0248 1 0>,
			<DCC_READ 0x190e5018 1 0>,
			<DCC_READ 0x190e5008 1 0>,
			<DCC_LOOP 0x6  0 0>,
			<DCC_READ 0x190e5010 2 0>,
			<DCC_LOOP 0x1 0 0>,
			<DCC_READ 0x3c40010 1 0>,
			<DCC_READ 0x3c40020 8 0>,
			<DCC_READ 0x3c4b048 1 0>,
			<DCC_READ 0x3c41018 1 0>,
			<DCC_READ 0x3c41008 1 0>,
			<DCC_LOOP 0x5  0 0>,
			<DCC_READ 0x3c41010 2 0>,
			<DCC_LOOP 0x1 0 0>,
			<DCC_READ 0x3002028 1 0>,
			<DCC_READ 0x30b0408 1 0>,
			<DCC_READ 0x30b0404 1 0>,
			<DCC_READ 0x3480408 1 0>,
			<DCC_READ 0x3480404 1 0>,
			<DCC_READ 0x1680010 1 0>,
			<DCC_READ 0x1680020 8 0>,
			<DCC_READ 0x1680248 1 0>,
			<DCC_READ 0x1681018 1 0>,
			<DCC_READ 0x1681008 1 0>,
			<DCC_LOOP 0x7  0 0>,
			<DCC_READ 0x1681010 2 0>,
			<DCC_LOOP 0x1 0 0>,
			<DCC_READ 0x1691010 1 0>,
			<DCC_READ 0x1697010 1 0>,
			<DCC_READ 0x1698010 1 0>,
			<DCC_READ 0x1694010 1 0>,
			<DCC_READ 0x1696010 1 0>,
			<DCC_READ 0x1699010 1 0>,
			<DCC_READ 0x16e0010 1 0>,
			<DCC_READ 0x16e0020 8 0>,
			<DCC_READ 0x16e0248 1 0>,
			<DCC_READ 0x1700010 1 0>,
			<DCC_READ 0x1700020 8 0>,
			<DCC_READ 0x1700248 1 0>,
			<DCC_READ 0x16c0010 1 0>,
			<DCC_READ 0x16c0020 8 0>,
			<DCC_READ 0x16c0248 1 0>,
			<DCC_READ 0x16e1018 1 0>,
			<DCC_READ 0x16e1008 1 0>,
			<DCC_LOOP 0x4  0 0>,
			<DCC_READ 0x16e1010 2 0>,
			<DCC_LOOP 0x1 0 0>,
			<DCC_READ 0x16c1018 1 0>,
			<DCC_READ 0x16c1008 1 0>,
			<DCC_LOOP 0x4  0 0>,
			<DCC_READ 0x16c1010 2 0>,
			<DCC_LOOP 0x1 0 0>,
			<DCC_READ 0x1701018 1 0>,
			<DCC_READ 0x1701008 1 0>,
			<DCC_LOOP 0x5  0 0>,
			<DCC_READ 0x1701010 2 0>,
			<DCC_LOOP 0x1 0 0>,
			<DCC_READ 0x16e9010 1 0>,
			<DCC_READ 0x16ea010 1 0>,
			<DCC_READ 0x16eb010 1 0>,
			<DCC_READ 0x1710010 1 0>,
			<DCC_READ 0x1714010 1 0>,
			<DCC_READ 0x1711010 1 0>,
			<DCC_READ 0x170e010 1 0>,
			<DCC_READ 0x170f010 1 0>,
			<DCC_READ 0x1712010 1 0>,
			<DCC_READ 0x1713010 1 0>,
			<DCC_READ 0x1715010 1 0>,
			<DCC_READ 0x1500010 1 0>,
			<DCC_READ 0x1500020 8 0>,
			<DCC_READ 0x1500248 2 0>,
			<DCC_READ 0x1500258 1 0>,
			<DCC_READ 0x1500448 1 0>,
			<DCC_READ 0x1512018 1 0>,
			<DCC_READ 0x1512008 1 0>,
			<DCC_LOOP 0x3  0 0>,
			<DCC_READ 0x1512010 2 0>,
			<DCC_LOOP 0x1 0 0>,
			<DCC_READ 0x1513018 1 0>,
			<DCC_READ 0x1513008 1 0>,
			<DCC_LOOP 0x4  0 0>,
			<DCC_READ 0x1513010 2 0>,
			<DCC_LOOP 0x1 0 0>,
			<DCC_READ 0x1510018 1 0>,
			<DCC_READ 0x1510008 1 0>,
			<DCC_LOOP 0xb  0 0>,
			<DCC_READ 0x1510010 2 0>,
			<DCC_LOOP 0x1 0 0>,
			<DCC_READ 0x1847ac 1 0>,
			<DCC_READ 0x17100104 29 0>,
			<DCC_READ 0x17100204 29 0>,
			<DCC_READ 0x17100384 29 0>,
			<DCC_READ 0x178a0250 2 0>,
			<DCC_READ 0x178a025c 1 0>,
			<DCC_READ 0xb281024 1 0>,
			<DCC_READ 0xbde1034 1 0>,
			<DCC_READ 0xb201020 2 0>,
			<DCC_READ 0xb211020 2 0>,
			<DCC_READ 0xb221020 2 0>,
			<DCC_READ 0xb231020 2 0>,
			<DCC_READ 0xb204520 1 0>,
			<DCC_READ 0x17a00010 1 0>,
			<DCC_READ 0x17a10010 1 0>,
			<DCC_READ 0x17a20010 1 0>,
			<DCC_READ 0x17a30010 1 0>,
			<DCC_READ 0x17a00030 1 0>,
			<DCC_READ 0x17a10030 1 0>,
			<DCC_READ 0x17a20030 1 0>,
			<DCC_READ 0x17a30030 1 0>,
			<DCC_READ 0x17a00038 1 0>,
			<DCC_READ 0x17a10038 1 0>,
			<DCC_READ 0x17a20038 1 0>,
			<DCC_READ 0x17a30038 1 0>,
			<DCC_READ 0x17a00040 1 0>,
			<DCC_READ 0x17a10040 1 0>,
			<DCC_READ 0x17a20040 1 0>,
			<DCC_READ 0x17a30040 1 0>,
			<DCC_READ 0x17a00048 1 0>,
			<DCC_READ 0x17a00400 3 0>,
			<DCC_READ 0x17a10400 3 0>,
			<DCC_READ 0x17a20400 3 0>,
			<DCC_READ 0x17a30400 3 0>,
			<DCC_READ 0xc230000 6 0>,
			<DCC_READ 0x17b020 1 0>,
			<DCC_READ 0x17b030 1 0>,
			<DCC_READ 0x17b028 1 0>,
			<DCC_READ 0x120004 1 0>,
			<DCC_READ 0x193008 1 0>,
			<DCC_READ 0x18b02c 1 0>,
			<DCC_READ 0x17d80100 256 0>,
			<DCC_READ 0x17120000 1 0>,
			<DCC_READ 0x17120008 1 0>,
			<DCC_READ 0x17120010 1 0>,
			<DCC_READ 0x17120018 1 0>,
			<DCC_READ 0x17120020 1 0>,
			<DCC_READ 0x17120028 1 0>,
			<DCC_READ 0x17120040 1 0>,
			<DCC_READ 0x17120048 1 0>,
			<DCC_READ 0x17120050 1 0>,
			<DCC_READ 0x17120058 1 0>,
			<DCC_READ 0x17120060 1 0>,
			<DCC_READ 0x17120068 1 0>,
			<DCC_READ 0x17120080 1 0>,
			<DCC_READ 0x17120088 1 0>,
			<DCC_READ 0x17120090 1 0>,
			<DCC_READ 0x17120098 1 0>,
			<DCC_READ 0x171200a0 1 0>,
			<DCC_READ 0x171200a8 1 0>,
			<DCC_READ 0x171200c0 1 0>,
			<DCC_READ 0x171200c8 1 0>,
			<DCC_READ 0x171200d0 1 0>,
			<DCC_READ 0x171200d8 1 0>,
			<DCC_READ 0x171200e0 1 0>,
			<DCC_READ 0x171200e8 1 0>,
			<DCC_READ 0x17120100 1 0>,
			<DCC_READ 0x17120108 1 0>,
			<DCC_READ 0x17120110 1 0>,
			<DCC_READ 0x17120118 1 0>,
			<DCC_READ 0x17120120 1 0>,
			<DCC_READ 0x17120128 1 0>,
			<DCC_READ 0x17120140 1 0>,
			<DCC_READ 0x17120148 1 0>,
			<DCC_READ 0x17120150 1 0>,
			<DCC_READ 0x17120158 1 0>,
			<DCC_READ 0x17120160 1 0>,
			<DCC_READ 0x17120168 1 0>,
			<DCC_READ 0x17120180 1 0>,
			<DCC_READ 0x17120188 1 0>,
			<DCC_READ 0x17120190 1 0>,
			<DCC_READ 0x17120198 1 0>,
			<DCC_READ 0x171201a0 1 0>,
			<DCC_READ 0x171201a8 1 0>,
			<DCC_READ 0x171201c0 1 0>,
			<DCC_READ 0x171201c8 1 0>,
			<DCC_READ 0x171201d0 1 0>,
			<DCC_READ 0x171201d8 1 0>,
			<DCC_READ 0x171201e0 1 0>,
			<DCC_READ 0x171201e8 1 0>,
			<DCC_READ 0x17120200 1 0>,
			<DCC_READ 0x17120208 1 0>,
			<DCC_READ 0x17120210 1 0>,
			<DCC_READ 0x17120218 1 0>,
			<DCC_READ 0x17120220 1 0>,
			<DCC_READ 0x17120228 1 0>,
			<DCC_READ 0x17120240 1 0>,
			<DCC_READ 0x17120248 1 0>,
			<DCC_READ 0x17120250 1 0>,
			<DCC_READ 0x17120258 1 0>,
			<DCC_READ 0x17120260 1 0>,
			<DCC_READ 0x17120268 1 0>,
			<DCC_READ 0x17120280 1 0>,
			<DCC_READ 0x17120288 1 0>,
			<DCC_READ 0x17120290 1 0>,
			<DCC_READ 0x17120298 1 0>,
			<DCC_READ 0x171202a0 1 0>,
			<DCC_READ 0x171202a8 1 0>,
			<DCC_READ 0x171202c0 1 0>,
			<DCC_READ 0x171202c8 1 0>,
			<DCC_READ 0x171202d0 1 0>,
			<DCC_READ 0x171202d8 1 0>,
			<DCC_READ 0x171202e0 1 0>,
			<DCC_READ 0x171202e8 1 0>,
			<DCC_READ 0x17120300 1 0>,
			<DCC_READ 0x17120308 1 0>,
			<DCC_READ 0x17120310 1 0>,
			<DCC_READ 0x17120318 1 0>,
			<DCC_READ 0x17120320 1 0>,
			<DCC_READ 0x17120328 1 0>,
			<DCC_READ 0x17120340 1 0>,
			<DCC_READ 0x17120348 1 0>,
			<DCC_READ 0x17120350 1 0>,
			<DCC_READ 0x17120358 1 0>,
			<DCC_READ 0x17120360 1 0>,
			<DCC_READ 0x17120368 1 0>,
			<DCC_READ 0x17120380 1 0>,
			<DCC_READ 0x17120388 1 0>,
			<DCC_READ 0x17120390 1 0>,
			<DCC_READ 0x17120398 1 0>,
			<DCC_READ 0x171203a0 1 0>,
			<DCC_READ 0x171203a8 1 0>,
			<DCC_READ 0x171203c0 1 0>,
			<DCC_READ 0x171203c8 1 0>,
			<DCC_READ 0x171203d0 1 0>,
			<DCC_READ 0x171203d8 1 0>,
			<DCC_READ 0x171203e0 1 0>,
			<DCC_READ 0x171203e8 1 0>,
			<DCC_READ 0x17120400 1 0>,
			<DCC_READ 0x17120408 1 0>,
			<DCC_READ 0x17120410 1 0>,
			<DCC_READ 0x17120418 1 0>,
			<DCC_READ 0x17120420 1 0>,
			<DCC_READ 0x17120428 1 0>,
			<DCC_READ 0x17120440 1 0>,
			<DCC_READ 0x17120448 1 0>,
			<DCC_READ 0x17120450 1 0>,
			<DCC_READ 0x17120458 1 0>,
			<DCC_READ 0x17120460 1 0>,
			<DCC_READ 0x17120468 1 0>,
			<DCC_READ 0x17120480 1 0>,
			<DCC_READ 0x17120488 1 0>,
			<DCC_READ 0x17120490 1 0>,
			<DCC_READ 0x17120498 1 0>,
			<DCC_READ 0x171204a0 1 0>,
			<DCC_READ 0x171204a8 1 0>,
			<DCC_READ 0x171204c0 1 0>,
			<DCC_READ 0x171204c8 1 0>,
			<DCC_READ 0x171204d0 1 0>,
			<DCC_READ 0x171204d8 1 0>,
			<DCC_READ 0x171204e0 1 0>,
			<DCC_READ 0x171204e8 1 0>,
			<DCC_READ 0x17120500 1 0>,
			<DCC_READ 0x17120508 1 0>,
			<DCC_READ 0x17120510 1 0>,
			<DCC_READ 0x17120518 1 0>,
			<DCC_READ 0x17120520 1 0>,
			<DCC_READ 0x17120528 1 0>,
			<DCC_READ 0x17120540 1 0>,
			<DCC_READ 0x17120548 1 0>,
			<DCC_READ 0x17120550 1 0>,
			<DCC_READ 0x17120558 1 0>,
			<DCC_READ 0x17120560 1 0>,
			<DCC_READ 0x17120568 1 0>,
			<DCC_READ 0x17120580 1 0>,
			<DCC_READ 0x17120588 1 0>,
			<DCC_READ 0x17120590 1 0>,
			<DCC_READ 0x17120598 1 0>,
			<DCC_READ 0x171205a0 1 0>,
			<DCC_READ 0x171205a8 1 0>,
			<DCC_READ 0x171205c0 1 0>,
			<DCC_READ 0x171205c8 1 0>,
			<DCC_READ 0x171205d0 1 0>,
			<DCC_READ 0x171205d8 1 0>,
			<DCC_READ 0x171205e0 1 0>,
			<DCC_READ 0x171205e8 1 0>,
			<DCC_READ 0x17120600 1 0>,
			<DCC_READ 0x17120608 1 0>,
			<DCC_READ 0x17120610 1 0>,
			<DCC_READ 0x17120618 1 0>,
			<DCC_READ 0x17120620 1 0>,
			<DCC_READ 0x17120628 1 0>,
			<DCC_READ 0x17120640 1 0>,
			<DCC_READ 0x17120648 1 0>,
			<DCC_READ 0x17120650 1 0>,
			<DCC_READ 0x17120658 1 0>,
			<DCC_READ 0x17120660 1 0>,
			<DCC_READ 0x17120668 1 0>,
			<DCC_READ 0x17120680 1 0>,
			<DCC_READ 0x17120688 1 0>,
			<DCC_READ 0x17120690 1 0>,
			<DCC_READ 0x17120698 1 0>,
			<DCC_READ 0x171206a0 1 0>,
			<DCC_READ 0x171206a8 1 0>,
			<DCC_READ 0x171206c0 1 0>,
			<DCC_READ 0x171206c8 1 0>,
			<DCC_READ 0x171206d0 1 0>,
			<DCC_READ 0x171206d8 1 0>,
			<DCC_READ 0x171206e0 1 0>,
			<DCC_READ 0x171206e8 1 0>,
			<DCC_READ 0x1712e000 1 0>,
			<DCC_READ 0x192d2400 2 0>,
			<DCC_READ 0x192d2410 1 0>,
			<DCC_READ 0x192d2418 1 0>,
			<DCC_READ 0x192d1400 2 0>,
			<DCC_READ 0x192d1410 3 0>,
			<DCC_READ 0x192d1420 2 0>,
			<DCC_READ 0x192d1430 1 0>,
			<DCC_READ 0x192d1440 1 0>,
			<DCC_READ 0x192d0400 2 0>,
			<DCC_READ 0x192d0410 3 0>,
			<DCC_READ 0x192d0420 2 0>,
			<DCC_READ 0x192d0430 1 0>,
			<DCC_READ 0x192d0440 1 0>,
			<DCC_READ 0x192d0448 1 0>,
			<DCC_READ 0x192d04a0 1 0>,
			<DCC_READ 0x192d04b0 4 0>,
			<DCC_READ 0x192d04d0 2 0>,
			<DCC_READ 0x192d04e0 1 0>,
			<DCC_READ 0x192d3400 5 0>,
			<DCC_READ 0x192d5110 1 0>,
			<DCC_READ 0x192d5210 1 0>,
			<DCC_READ 0x192d5230 1 0>,
			<DCC_READ 0x192d53b0 2 0>,
			<DCC_READ 0x192d5840 1 0>,
			<DCC_READ 0x192d5920 4 0>,
			<DCC_READ 0x192d5b00 8 0>,
			<DCC_READ 0x192d5b28 1 0>,
			<DCC_READ 0x192d5b30 3 0>,
			<DCC_READ 0x192d6400 1 0>,
			<DCC_READ 0x192d6410 1 0>,
			<DCC_READ 0x192d6418 1 0>,
			<DCC_READ 0x192d6420 1 0>,
			<DCC_READ 0x193d0400 2 0>,
			<DCC_READ 0x193d0410 3 0>,
			<DCC_READ 0x193d0420 2 0>,
			<DCC_READ 0x193d0430 1 0>,
			<DCC_READ 0x193d0440 1 0>,
			<DCC_READ 0x193d0448 1 0>,
			<DCC_READ 0x193d04a0 1 0>,
			<DCC_READ 0x193d04b0 4 0>,
			<DCC_READ 0x193d04d0 2 0>,
			<DCC_READ 0x193d04e0 1 0>,
			<DCC_READ 0x192d0400 2 0>,
			<DCC_READ 0x192d0410 3 0>,
			<DCC_READ 0x192d0420 2 0>,
			<DCC_READ 0x192d0430 1 0>,
			<DCC_READ 0x192d0440 1 0>,
			<DCC_READ 0x192d0448 1 0>,
			<DCC_READ 0x192d04a0 1 0>,
			<DCC_READ 0x192d04b0 4 0>,
			<DCC_READ 0x192d04d0 2 0>,
			<DCC_READ 0x192d04e0 1 0>,
			<DCC_READ 0x192d1400 2 0>,
			<DCC_READ 0x192d1410 3 0>,
			<DCC_READ 0x192d1420 2 0>,
			<DCC_READ 0x192d1430 1 0>,
			<DCC_READ 0x192d1440 1 0>,
			<DCC_READ 0x192d2400 2 0>,
			<DCC_READ 0x192d2410 1 0>,
			<DCC_READ 0x192d2418 1 0>,
			<DCC_READ 0x192d3400 5 0>,
			<DCC_READ 0x192d5110 1 0>,
			<DCC_READ 0x192d5210 1 0>,
			<DCC_READ 0x192d5230 1 0>,
			<DCC_READ 0x192d53b0 2 0>,
			<DCC_READ 0x192d5840 1 0>,
			<DCC_READ 0x192d5920 4 0>,
			<DCC_READ 0x192d5b00 8 0>,
			<DCC_READ 0x192d5b28 5 0>,
			<DCC_READ 0x192d6400 1 0>,
			<DCC_READ 0x192d6410 1 0>,
			<DCC_READ 0x192d6418 1 0>,
			<DCC_READ 0x192d6420 1 0>,
			<DCC_READ 0x192d9100 1 0>,
			<DCC_READ 0xec80010 1 0>,
			<DCC_READ 0xec81000 1 0>,
			<DCC_READ 0xec81010 16 0>,
			<DCC_READ 0xec81050 16 0>,
			<DCC_READ 0xec81090 16 0>,
			<DCC_READ 0xec810d0 16 0>,
			<DCC_READ 0xec811d0 16 0>,
			<DCC_READ 0x32310220 3 0>,
			<DCC_READ 0x323102a0 3 0>,
			<DCC_READ 0x323104a0 6 0>,
			<DCC_READ 0x32310520 1 0>,
			<DCC_READ 0x32310588 1 0>,
			<DCC_READ 0x32310d10 8 0>,
			<DCC_READ 0x32310f90 6 0>,
			<DCC_READ 0x32311010 6 0>,
			<DCC_READ 0x32311a10 3 0>,
			<DCC_READ 0x323b0208 1 0>,
			<DCC_READ 0x323b0228 1 0>,
			<DCC_READ 0x323b0248 1 0>,
			<DCC_READ 0x323b0268 1 0>,
			<DCC_READ 0x323b0288 1 0>,
			<DCC_READ 0x323b02a8 1 0>,
			<DCC_READ 0x323b020c 1 0>,
			<DCC_READ 0x323b022c 1 0>,
			<DCC_READ 0x323b024c 1 0>,
			<DCC_READ 0x323b026c 1 0>,
			<DCC_READ 0x323b028c 1 0>,
			<DCC_READ 0x323b02ac 1 0>,
			<DCC_READ 0x323b0210 1 0>,
			<DCC_READ 0x323b0230 1 0>,
			<DCC_READ 0x323b0250 1 0>,
			<DCC_READ 0x323b0270 1 0>,
			<DCC_READ 0x323b0290 1 0>,
			<DCC_READ 0x323b02b0 1 0>,
			<DCC_READ 0x323b0400 1 0>,
			<DCC_READ 0x323b0404 1 0>,
			<DCC_READ 0x323b0408 1 0>,
			<DCC_READ 0x320a4400 1 0>,
			<DCC_READ 0x320a4404 1 0>,
			<DCC_READ 0x320a4408 1 0>,
			<DCC_READ 0x32302028 1 0>,
			<DCC_READ 0x32300304 1 0>,
			<DCC_READ 0x320a4408 1 0>,
			<DCC_READ 0x320a4400 1 0>,
			<DCC_READ 0x320a4208 1 0>,
			<DCC_READ 0x320b4208 1 0>,
			<DCC_READ 0x320c4208 1 0>,
			<DCC_READ 0x320d4208 1 0>,
			<DCC_READ 0x320a420c 1 0>,
			<DCC_READ 0x320b420c 1 0>,
			<DCC_READ 0x320c420c 1 0>,
			<DCC_READ 0x320d420c 1 0>,
			<DCC_READ 0x320a7d4c 1 0>,
			<DCC_READ 0x323b0208 1 0>,
			<DCC_READ 0x323c0208 1 0>,
			<DCC_READ 0x323d0208 1 0>,
			<DCC_READ 0x323e0208 1 0>,
			<DCC_READ 0x323b020c 1 0>,
			<DCC_READ 0x323c020c 1 0>,
			<DCC_READ 0x323d020c 1 0>,
			<DCC_READ 0x323e020c 1 0>,
			<DCC_READ 0xb2b1024 1 0>,
			<DCC_READ 0xb2b4520 1 0>,
			<DCC_READ 0xb2b1204 1 0>,
			<DCC_READ 0xb2b1218 1 0>,
			<DCC_READ 0xb2b122c 1 0>,
			<DCC_READ 0xb2b1240 1 0>,
			<DCC_READ 0xb2b1208 1 0>,
			<DCC_READ 0xb2b121c 1 0>,
			<DCC_READ 0xb2b1230 1 0>,
			<DCC_READ 0xb2b1244 1 0>,
			<DCC_READ 0x30b0208 1 0>,
			<DCC_READ 0x30b0228 1 0>,
			<DCC_READ 0x30b0248 1 0>,
			<DCC_READ 0x30b0268 1 0>,
			<DCC_READ 0x30b0288 1 0>,
			<DCC_READ 0x30b02a8 1 0>,
			<DCC_READ 0x30b020c 1 0>,
			<DCC_READ 0x30b022c 1 0>,
			<DCC_READ 0x30b024c 1 0>,
			<DCC_READ 0x30b026c 1 0>,
			<DCC_READ 0x30b028c 1 0>,
			<DCC_READ 0x30b02ac 1 0>,
			<DCC_READ 0x30b0210 1 0>,
			<DCC_READ 0x30b0230 1 0>,
			<DCC_READ 0x30b0250 1 0>,
			<DCC_READ 0x30b0270 1 0>,
			<DCC_READ 0x30b0290 1 0>,
			<DCC_READ 0x30b02b0 1 0>,
			<DCC_READ 0x30b0400 1 0>,
			<DCC_READ 0x30b0404 1 0>,
			<DCC_READ 0x30b0408 1 0>,
			<DCC_READ 0x3480400 1 0>,
			<DCC_READ 0x3480404 1 0>,
			<DCC_READ 0x3480408 1 0>,
			<DCC_READ 0x3002028 1 0>,
			<DCC_READ 0x3000304 1 0>,
			<DCC_READ 0x3480408 1 0>,
			<DCC_READ 0x3480400 1 0>,
			<DCC_READ 0x3480208 1 0>,
			<DCC_READ 0x3490208 1 0>,
			<DCC_READ 0x3480204 1 0>,
			<DCC_READ 0x3490204 1 0>,
			<DCC_READ 0x3483d4c 1 0>,
			<DCC_READ 0x30b0208 1 0>,
			<DCC_READ 0x30c0208 1 0>,
			<DCC_READ 0x30d0208 1 0>,
			<DCC_READ 0x30e0208 1 0>,
			<DCC_READ 0x30b020c 1 0>,
			<DCC_READ 0x30c020c 1 0>,
			<DCC_READ 0x30d020c 1 0>,
			<DCC_READ 0x30e020c 1 0>,
			<DCC_READ 0xb251024 1 0>,
			<DCC_READ 0xb254520 1 0>,
			<DCC_READ 0xb251218 1 0>,
			<DCC_READ 0xb25122c 1 0>,
			<DCC_READ 0xb251240 1 0>,
			<DCC_READ 0xb251254 1 0>,
			<DCC_READ 0xb251208 1 0>,
			<DCC_READ 0xb25121c 1 0>,
			<DCC_READ 0xb251230 1 0>,
			<DCC_READ 0xb251244 1 0>,
			<DCC_READ 0x4130208 1 0>,
			<DCC_READ 0x4130228 1 0>,
			<DCC_READ 0x4130248 1 0>,
			<DCC_READ 0x4130268 1 0>,
			<DCC_READ 0x4130288 1 0>,
			<DCC_READ 0x41302a8 1 0>,
			<DCC_READ 0x413020c 1 0>,
			<DCC_READ 0x413022c 1 0>,
			<DCC_READ 0x413024c 1 0>,
			<DCC_READ 0x413026c 1 0>,
			<DCC_READ 0x413028c 1 0>,
			<DCC_READ 0x41302ac 1 0>,
			<DCC_READ 0x4130210 1 0>,
			<DCC_READ 0x4130230 1 0>,
			<DCC_READ 0x4130250 1 0>,
			<DCC_READ 0x4130270 1 0>,
			<DCC_READ 0x4130290 1 0>,
			<DCC_READ 0x41302b0 1 0>,
			<DCC_READ 0x4130400 1 0>,
			<DCC_READ 0x4130404 1 0>,
			<DCC_READ 0x4130408 1 0>,
			<DCC_READ 0x4200400 1 0>,
			<DCC_READ 0x4200404 1 0>,
			<DCC_READ 0x4200408 1 0>,
			<DCC_READ 0x4082028 1 0>,
			<DCC_READ 0x4080304 1 0>,
			<DCC_READ 0x4200408 1 0>,
			<DCC_READ 0x4200400 1 0>,
			<DCC_READ 0x4200208 1 0>,
			<DCC_READ 0x4210208 1 0>,
			<DCC_READ 0x4220208 1 0>,
			<DCC_READ 0x4230208 1 0>,
			<DCC_READ 0x420020c 1 0>,
			<DCC_READ 0x421020c 1 0>,
			<DCC_READ 0x422020c 1 0>,
			<DCC_READ 0x423020c 1 0>,
			<DCC_READ 0x4203d4c 1 0>,
			<DCC_READ 0x4130208 1 0>,
			<DCC_READ 0x4140208 1 0>,
			<DCC_READ 0x4150208 1 0>,
			<DCC_READ 0x4160208 1 0>,
			<DCC_READ 0x413020c 1 0>,
			<DCC_READ 0x414020c 1 0>,
			<DCC_READ 0x415020c 1 0>,
			<DCC_READ 0x416020c 1 0>,
			<DCC_READ 0xb2f1024 1 0>,
			<DCC_READ 0xb2f4520 1 0>,
			<DCC_READ 0xb2f1204 1 0>,
			<DCC_READ 0xb2f1218 1 0>,
			<DCC_READ 0xb2f122c 1 0>,
			<DCC_READ 0xb2f1240 1 0>,
			<DCC_READ 0xb2f1208 1 0>,
			<DCC_READ 0xb2f121c 1 0>,
			<DCC_READ 0xb2f1230 1 0>,
			<DCC_READ 0xb2f1244 1 0>,
			<DCC_READ 0x8ab0208 1 0>,
			<DCC_READ 0x8ab0228 1 0>,
			<DCC_READ 0x8ab0248 1 0>,
			<DCC_READ 0x8ab0268 1 0>,
			<DCC_READ 0x8ab0288 1 0>,
			<DCC_READ 0x8ab02a8 1 0>,
			<DCC_READ 0x8ab020c 1 0>,
			<DCC_READ 0x8ab022c 1 0>,
			<DCC_READ 0x8ab024c 1 0>,
			<DCC_READ 0x8ab026c 1 0>,
			<DCC_READ 0x8ab028c 1 0>,
			<DCC_READ 0x8ab02ac 1 0>,
			<DCC_READ 0x8ab0210 1 0>,
			<DCC_READ 0x8ab0230 1 0>,
			<DCC_READ 0x8ab0250 1 0>,
			<DCC_READ 0x8ab0270 1 0>,
			<DCC_READ 0x8ab0290 1 0>,
			<DCC_READ 0x8ab02b0 1 0>,
			<DCC_READ 0x8ab0400 1 0>,
			<DCC_READ 0x8ab0404 1 0>,
			<DCC_READ 0x8ab0408 1 0>,
			<DCC_READ 0x8b00400 1 0>,
			<DCC_READ 0x8b00404 1 0>,
			<DCC_READ 0x8b00408 1 0>,
			<DCC_READ 0xb2e1024 1 0>,
			<DCC_READ 0xb2e4520 1 0>,
			<DCC_READ 0xb2e1204 1 0>,
			<DCC_READ 0xb2e1218 1 0>,
			<DCC_READ 0xb2e122c 1 0>,
			<DCC_READ 0xb2e1240 1 0>,
			<DCC_READ 0xb2e1208 1 0>,
			<DCC_READ 0xb2e1244 1 0>,
			<DCC_READ 0xb2e1258 1 0>,
			<DCC_READ 0xb2e126c 1 0>,
			<DCC_READ 0x20c200f0 1 0>,
			<DCC_READ 0x20c200f4 1 0>,
			<DCC_READ 0x20c200f8 1 0>,
			<DCC_READ 0x20c200fc 1 0>,
			<DCC_READ 0x20c20100 1 0>,
			<DCC_READ 0x20c20104 1 0>,
			<DCC_READ 0x20c20108 1 0>,
			<DCC_READ 0x20c2010c 1 0>,
			<DCC_READ 0xb2c1024 1 0>,
			<DCC_READ 0xb2c4520 1 0>,
			<DCC_READ 0xb2c1204 1 0>,
			<DCC_READ 0xb2c1218 1 0>,
			<DCC_READ 0xb2c122c 1 0>,
			<DCC_READ 0xb2c1240 1 0>,
			<DCC_READ 0xb2c1208 1 0>,
			<DCC_READ 0xb2c121c 1 0>,
			<DCC_READ 0xb2c1230 1 0>,
			<DCC_READ 0xb2c1244 1 0>,
			<DCC_READ 0x136010 1 0>,
			<DCC_READ 0x136018 1 0>,
			<DCC_READ 0xac4d000 1 0>,
			<DCC_READ 0xac40000 1 0>,
			<DCC_READ 0xad150d0 1 0>,
			<DCC_READ 0xad10060 1 0>,
			<DCC_READ 0xad10064 1 0>,
			<DCC_READ 0xad10044 1 0>,
			<DCC_READ 0xad10048 1 0>,
			<DCC_READ 0xad10004 1 0>,
			<DCC_READ 0xad10008 1 0>,
			<DCC_READ 0xad10018 1 0>,
			<DCC_READ 0xad1001c 1 0>,
			<DCC_READ 0xad10030 1 0>,
			<DCC_READ 0xad10078 1 0>,
			<DCC_READ 0xad1005c 1 0>,
			<DCC_READ 0xad10000 1 0>,
			<DCC_READ 0xad10040 1 0>,
			<DCC_READ 0xad11004 1 0>,
			<DCC_READ 0xad11008 1 0>,
			<DCC_READ 0xad11018 1 0>,
			<DCC_READ 0xad1101c 1 0>,
			<DCC_READ 0xad11030 1 0>,
			<DCC_READ 0xad11048 1 0>,
			<DCC_READ 0xad11044 1 0>,
			<DCC_READ 0xad11000 1 0>,
			<DCC_READ 0xad11040 1 0>,
			<DCC_READ 0xad15070 1 0>,
			<DCC_READ 0xad15074 1 0>,
			<DCC_READ 0xad15078 1 0>,
			<DCC_READ 0xad1508c 1 0>,
			<DCC_READ 0xad15094 1 0>,
			<DCC_READ 0xad13090 1 0>,
			<DCC_READ 0xad13000 1 0>,
			<DCC_READ 0xad13038 1 0>,
			<DCC_READ 0xad13008 1 0>,
			<DCC_READ 0xad13004 1 0>,
			<DCC_READ 0xad1308c 1 0>,
			<DCC_READ 0xad13030 1 0>,
			<DCC_READ 0xad13044 1 0>,
			<DCC_READ 0xad13018 1 0>,
			<DCC_READ 0xad1301c 1 0>,
			<DCC_READ 0xad13060 1 0>,
			<DCC_READ 0xad13048 1 0>,
			<DCC_READ 0xad1304c 1 0>,
			<DCC_READ 0xad14000 1 0>,
			<DCC_READ 0xad14038 1 0>,
			<DCC_READ 0xad14070 1 0>,
			<DCC_READ 0xad14008 1 0>,
			<DCC_READ 0xad14004 1 0>,
			<DCC_READ 0xad1406c 1 0>,
			<DCC_READ 0xad14060 1 0>,
			<DCC_READ 0xad14048 1 0>,
			<DCC_READ 0xad1404c 1 0>,
			<DCC_READ 0xad14030 1 0>,
			<DCC_READ 0xad14044 1 0>,
			<DCC_READ 0xad14018 1 0>,
			<DCC_READ 0xad1401c 1 0>,
			<DCC_READ 0xad14074 1 0>,
			<DCC_READ 0xad140ac 1 0>,
			<DCC_READ 0xad140e0 1 0>,
			<DCC_READ 0xad1407c 1 0>,
			<DCC_READ 0xad14078 1 0>,
			<DCC_READ 0xad140dc 1 0>,
			<DCC_READ 0xad140a4 1 0>,
			<DCC_READ 0xad1408c 1 0>,
			<DCC_READ 0xad14090 1 0>,
			<DCC_READ 0xad140d0 1 0>,
			<DCC_READ 0xad140b8 1 0>,
			<DCC_READ 0xad140bc 1 0>,
			<DCC_READ 0xad15040 1 0>,
			<DCC_READ 0xad15044 1 0>,
			<DCC_READ 0xad15018 1 0>,
			<DCC_READ 0xad15000 1 0>,
			<DCC_READ 0xad15004 1 0>,
			<DCC_READ 0xad15034 1 0>,
			<DCC_READ 0xad1501c 1 0>,
			<DCC_READ 0xad15020 1 0>,
			<DCC_READ 0xad150f0 1 0>,
			<DCC_READ 0xad150d4 1 0>,
			<DCC_READ 0xad150d8 1 0>,
			<DCC_READ 0xad15120 1 0>,
			<DCC_READ 0xad15124 1 0>,
			<DCC_READ 0xad15134 1 0>,
			<DCC_READ 0xad15150 1 0>,
			<DCC_READ 0xacef054 1 0>,
			<DCC_READ 0xac1001c 1 0>;
		};
	};

	mem_dump {
		compatible = "qcom,mem-dump";
		memory-region = <&dump_mem>;

		c0_context {
			qcom,dump-size = <0x800>;
			qcom,dump-id = <0x0>;
		};

		c100_context {
			qcom,dump-size = <0x800>;
			qcom,dump-id = <0x1>;
		};

		c200_context {
			qcom,dump-size = <0x800>;
			qcom,dump-id = <0x2>;
		};

		c300_context {
			qcom,dump-size = <0x800>;
			qcom,dump-id = <0x3>;
		};

		c400_context {
			qcom,dump-size = <0x800>;
			qcom,dump-id = <0x4>;
		};

		c500_context {
			qcom,dump-size = <0x800>;
			qcom,dump-id = <0x5>;
		};

		c600_context {
			qcom,dump-size = <0x800>;
			qcom,dump-id = <0x6>;
		};

		c700_context {
			qcom,dump-size = <0x800>;
			qcom,dump-id = <0x7>;
		};

		complex0_scan {
			qcom,dump-size = <0x4a100>;
			qcom,dump-id = <0x130>;
		};

		complex1_scan {
			qcom,dump-size = <0x4a100>;
			qcom,dump-id = <0x131>;
		};

		gold0_scan {
			qcom,dump-size = <0x5f700>;
			qcom,dump-id = <0x132>;
		};

		gold1_scan {
			qcom,dump-size = <0x5f700>;
			qcom,dump-id = <0x133>;
		};

		gold2_scan {
			qcom,dump-size = <0x5f700>;
			qcom,dump-id = <0x134>;
		};

		gold3_scan {
			qcom,dump-size = <0x81100>;
			qcom,dump-id = <0x135>;
		};

		l3slice0scan {
			qcom,dump-size = <0x4cd00>;
			qcom,dump-id = <0x136>;
		};

		l3slice1scan {
			qcom,dump-size = <0x14e00>;
			qcom,dump-id = <0x137>;
		};

		l3slice2scan {
			qcom,dump-size = <0x14e00>;
			qcom,dump-id = <0x138>;
		};

		l3slice3scan {
			qcom,dump-size = <0x14e00>;
			qcom,dump-id = <0x139>;
		};

		mhm_scan {
			qcom,dump-size = <0x5a700>;
			qcom,dump-id = <0x161>;
		};

		l1_icache0 {
			qcom,dump-size = <0x11100>;
			qcom,dump-id = <0x60>;
		};

		l1_icache100 {
			qcom,dump-size = <0x11100>;
			qcom,dump-id = <0x61>;
		};

		l1_icache200 {
			qcom,dump-size = <0x11100>;
			qcom,dump-id = <0x62>;
		};

		l1_icache300 {
			qcom,dump-size = <0x11100>;
			qcom,dump-id = <0x63>;
		};

		l1_icache400 {
			qcom,dump-size = <0x11100>;
			qcom,dump-id = <0x64>;
		};

		l1_icache500 {
			qcom,dump-size = <0x11100>;
			qcom,dump-id = <0x65>;
		};

		l1_icache600 {
			qcom,dump-size = <0x11100>;
			qcom,dump-id = <0x66>;
		};

		l1_icache700 {
			qcom,dump-size = <0x22100>;
			qcom,dump-id = <0x67>;
		};

		l1_dcache0 {
			qcom,dump-size = <0x9100>;
			qcom,dump-id = <0x80>;
		};

		l1_dcache100 {
			qcom,dump-size = <0x9100>;
			qcom,dump-id = <0x81>;
		};

		l1_dcache200 {
			qcom,dump-size = <0x9100>;
			qcom,dump-id = <0x82>;
		};

		l1_dcache300 {
			qcom,dump-size = <0x9100>;
			qcom,dump-id = <0x83>;
		};

		l1_dcache400 {
			qcom,dump-size = <0xd100>;
			qcom,dump-id = <0x84>;
		};

		l1_dcache500 {
			qcom,dump-size = <0xd100>;
			qcom,dump-id = <0x85>;
		};

		l1_dcache600 {
			qcom,dump-size = <0xd100>;
			qcom,dump-id = <0x86>;
		};

		l1_dcache700 {
			qcom,dump-size = <0x1a100>;
			qcom,dump-id = <0x87>;
		};

		l1_itlb400 {
			qcom,dump-size = <0x600>;
			qcom,dump-id = <0x24>;
		};

		l1_itlb500 {
			qcom,dump-size = <0x600>;
			qcom,dump-id = <0x25>;
		};

		l1_itlb600 {
			qcom,dump-size = <0x600>;
			qcom,dump-id = <0x26>;
		};

		l1_itlb700 {
			qcom,dump-size = <0x600>;
			qcom,dump-id = <0x27>;
		};

		l1_dtlb400 {
			qcom,dump-size = <0x600>;
			qcom,dump-id = <0x44>;
		};

		l1_dtlb500 {
			qcom,dump-size = <0x600>;
			qcom,dump-id = <0x45>;
		};

		l1_dtlb600 {
			qcom,dump-size = <0x600>;
			qcom,dump-id = <0x46>;
		};

		l1_dtlb700 {
			qcom,dump-size = <0x600>;
			qcom,dump-id = <0x47>;
		};

		l2_cache0 {
			qcom,dump-size = <0x24100>;
			qcom,dump-id = <0xc0>;
		};

		l2_cache100 {
			qcom,dump-size = <0x24100>;
			qcom,dump-id = <0xc1>;
		};

		l2_cache200 {
			qcom,dump-size = <0x24100>;
			qcom,dump-id = <0xc2>;
		};

		l2_cache300 {
			qcom,dump-size = <0x24100>;
			qcom,dump-id = <0xc3>;
		};

		l2_cache400 {
			qcom,dump-size = <0xd0100>;
			qcom,dump-id = <0xc4>;
		};

		l2_cache500 {
			qcom,dump-size = <0xd0100>;
			qcom,dump-id = <0xc5>;
		};

		l2_cache600 {
			qcom,dump-size = <0xd0100>;
			qcom,dump-id = <0xc6>;
		};

		l2_cache700 {
			qcom,dump-size = <0x1a0100>;
			qcom,dump-id = <0xc7>;
		};

		l2_tlb0 {
			qcom,dump-size = <0xf700>;
			qcom,dump-id = <0x120>;
		};

		l2_tlb100 {
			qcom,dump-size = <0xf700>;
			qcom,dump-id = <0x121>;
		};

		l2_tlb200 {
			qcom,dump-size = <0xf700>;
			qcom,dump-id = <0x122>;
		};

		l2_tlb300 {
			qcom,dump-size = <0xf700>;
			qcom,dump-id = <0x123>;
		};

		l2_tlb400 {
			qcom,dump-size = <0xc100>;
			qcom,dump-id = <0x124>;
		};

		l2_tlb500 {
			qcom,dump-size = <0xc100>;
			qcom,dump-id = <0x125>;
		};

		l2_tlb600 {
			qcom,dump-size = <0xc100>;
			qcom,dump-id = <0x126>;
		};

		l2_tlb700 {
			qcom,dump-size = <0xc100>;
			qcom,dump-id = <0x127>;
		};

		l1dcdirty0 {
			qcom,dump-size = <0x1100>;
			qcom,dump-id = <0x170>;
		};

		l1dcdirty100 {
			qcom,dump-size = <0x1100>;
			qcom,dump-id = <0x171>;
		};

		l1dcdirty200 {
			qcom,dump-size = <0x1100>;
			qcom,dump-id = <0x172>;
		};

		l1dcdirty300 {
			qcom,dump-size = <0x1100>;
			qcom,dump-id = <0x173>;
		};

		l1dcmte0 {
			qcom,dump-size = <0x1100>;
			qcom,dump-id = <0x180>;
		};

		l1dcmte100 {
			qcom,dump-size = <0x1100>;
			qcom,dump-id = <0x181>;
		};

		l1dcmte200 {
			qcom,dump-size = <0x1100>;
			qcom,dump-id = <0x182>;
		};

		l1dcmte300 {
			qcom,dump-size = <0x1100>;
			qcom,dump-id = <0x183>;
		};

		l2dcmte0 {
			qcom,dump-size = <0x4100>;
			qcom,dump-id = <0x190>;
		};

		l2dcmte100 {
			qcom,dump-size = <0x4100>;
			qcom,dump-id = <0x191>;
		};

		l2dcmte200 {
			qcom,dump-size = <0x4100>;
			qcom,dump-id = <0x192>;
		};

		l2dcmte300 {
			qcom,dump-size = <0x4100>;
			qcom,dump-id = <0x193>;
		};

		l0mopca400 {
			qcom,dump-size = <0x6100>;
			qcom,dump-id = <0x1a4>;
		};

		l0mopca500 {
			qcom,dump-size = <0x6100>;
			qcom,dump-id = <0x1a5>;
		};

		l0mopca600 {
			qcom,dump-size = <0x6100>;
			qcom,dump-id = <0x1a6>;
		};

		l0mopca700 {
			qcom,dump-size = <0xc100>;
			qcom,dump-id = <0x1a7>;
		};

		l1btb400 {
			qcom,dump-size = <0x10100>;
			qcom,dump-id = <0x1b4>;
		};

		l1btb500 {
			qcom,dump-size = <0x10100>;
			qcom,dump-id = <0x1b5>;
		};

		l1btb600 {
			qcom,dump-size = <0x10100>;
			qcom,dump-id = <0x1b6>;
		};

		l1btb700 {
			qcom,dump-size = <0x10100>;
			qcom,dump-id = <0x1b7>;
		};

		l1ghb400 {
			qcom,dump-size = <0x4100>;
			qcom,dump-id = <0x1c4>;
		};

		l1ghb500 {
			qcom,dump-size = <0x4100>;
			qcom,dump-id = <0x1c5>;
		};

		l1ghb600 {
			qcom,dump-size = <0x4100>;
			qcom,dump-id = <0x1c6>;
		};

		l1ghb700 {
			qcom,dump-size = <0x8100>;
			qcom,dump-id = <0x1c7>;
		};

		l1bim400 {
			qcom,dump-size = <0x2100>;
			qcom,dump-id = <0x1d4>;
		};

		l1bim500 {
			qcom,dump-size = <0x2100>;
			qcom,dump-id = <0x1d5>;
		};

		l1bim600 {
			qcom,dump-size = <0x2100>;
			qcom,dump-id = <0x1d6>;
		};

		l1bim700 {
			qcom,dump-size = <0x4100>;
			qcom,dump-id = <0x1d7>;
		};

		l2victim400 {
			qcom,dump-size = <0x2100>;
			qcom,dump-id = <0x1e4>;
		};

		l2victim500 {
			qcom,dump-size = <0x2100>;
			qcom,dump-id = <0x1e5>;
		};

		l2victim600 {
			qcom,dump-size = <0x2100>;
			qcom,dump-id = <0x1e6>;
		};

		l2victim700 {
			qcom,dump-size = <0x4100>;
			qcom,dump-id = <0x1e7>;
		};

		cpuss_reg {
			qcom,dump-size = <0x30000>;
			qcom,dump-id = <0xef>;
		};

		rpmh {
			qcom,dump-size = <0x400000>;
			qcom,dump-id = <0xec>;
		};

		rpm_sw {
			qcom,dump-size = <0x28000>;
			qcom,dump-id = <0xea>;
		};

		pmic {
			qcom,dump-size = <0x200000>;
			qcom,dump-id = <0xe4>;
		};

		fcm {
			qcom,dump-size = <0x8400>;
			qcom,dump-id = <0xee>;
		};

		etf_swao {
			qcom,dump-size = <0x10000>;
			qcom,dump-id = <0xf1>;
		};

		etr_reg {
			qcom,dump-size = <0x1000>;
			qcom,dump-id = <0x100>;
		};

		etfswao_reg {
			qcom,dump-size = <0x1000>;
			qcom,dump-id = <0x102>;
		};

		etr1_reg {
			qcom,dump-size = <0x1000>;
			qcom,dump-id = <0x105>;
		};

		misc_data {
			qcom,dump-size = <0x1000>;
			qcom,dump-id = <0xe8>;
		};

		etf_slpi {
			qcom,dump-size = <0x4000>;
			qcom,dump-id = <0xf3>;
		};

		etfslpi_reg {
			qcom,dump-size = <0x1000>;
			qcom,dump-id = <0x103>;
		};

		etf_lpass {
			qcom,dump-size = <0x4000>;
			qcom,dump-id = <0xf4>;
		};

		etflpass_reg {
			qcom,dump-size = <0x1000>;
			qcom,dump-id = <0x104>;
		};

		osm_reg {
			qcom,dump-size = <0x400>;
			qcom,dump-id = <0x163>;
		};

		pcu_reg {
			qcom,dump-size = <0x400>;
			qcom,dump-id = <0x164>;
		};

		fsm_data {
			qcom,dump-size = <0x400>;
			qcom,dump-id = <0x165>;
		};

	};
};

